VERSION ""

NS_ :

BS_:

BU_: FUSION CCU EOP_R BMS MCU_F Shifter EOP_F MCU_R

BO_ 278 FD_VCU1: 8 FUSION
 SG_ PwrSta : 63|3@0+ (1,0) [0|5] "" CCU,EOP_R,BMS,MCU_F,Shifter,EOP_F,MCU_R
 SG_ DCDCVoltSetpoint : 55|8@0+ (0.0235,12) [12|17.9925] "V" CCU
 SG_ DCDCEnaReq : 40|1@0+ (1,0) [0|1] "" CCU
 SG_ Fr_MCUEnaReq : 41|1@0+ (1,0) [0|1] "" MCU_F
 SG_ Rr_MCUEnaReq : 42|1@0+ (1,0) [0|1] "" MCU_R
 SG_ HVBatCnctReq : 43|1@0+ (1,0) [0|1] "" BMS
 SG_ ActiveDischReq : 44|1@0+ (1,0) [0|1] "" MCU_F,MCU_R
 SG_ PrkReq : 45|1@0+ (1,0) [0|1] "" Vector__XXX
 SG_ Fr_ActvDmpDisabReq : 46|1@0+ (1,0) [0|1] "" MCU_F
 SG_ Rr_ActvDmpDisabReq : 47|1@0+ (1,0) [0|1] "" MCU_R
 SG_ HVSysReadyToCharge : 33|2@0+ (1,0) [0|3] "" CCU
 SG_ ShiftGearPosn : 38|3@0+ (1,0) [0|7] "" MCU_F,Shifter,MCU_R
 SG_ LVChrgFuncStaChk : 25|2@0+ (1,0) [0|2] "" Vector__XXX
 SG_ MSA_Crl_Sta : 31|3@0+ (1,0) [0|7] "" Vector__XXX
 SG_ DemoModeStaChk : 17|2@0+ (1,0) [0|2] "" Vector__XXX
 SG_ CoastDwModeStaChk : 19|2@0+ (1,0) [0|2] "" Vector__XXX
 SG_ DynoModeStaChk : 21|2@0+ (1,0) [0|2] "" Vector__XXX
 SG_ Dr_SeatSta : 23|2@0+ (1,0) [0|2] "" Vector__XXX
 SG_ RC_VCU1 : 15|4@0+ (1,0) [0|14] "" CCU,BMS,MCU_F,MCU_R
 SG_ CS_VCU1 : 7|8@0+ (1,0) [0|255] "" CCU,BMS,MCU_F,MCU_R

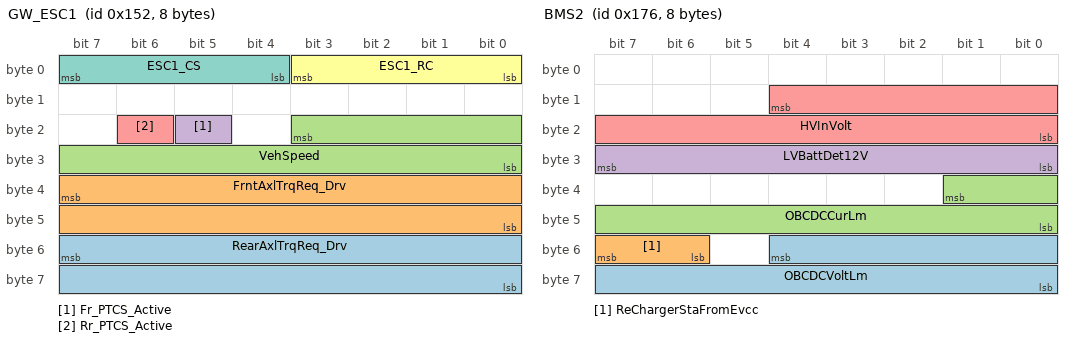
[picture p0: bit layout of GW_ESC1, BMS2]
BO_ 338 GW_ESC1: 8 FUSION
 SG_ RearAxlTrqReq_Drv : 55|16@0+ (0.5,-5300) [0|5300] "Nm" Vector__XXX
 SG_ FrntAxlTrqReq_Drv : 39|16@0+ (0.5,-5300) [0|5300] "Nm" Vector__XXX
 SG_ VehSpeed : 19|12@0+ (0.125,0) [0|255.875] "km/h" CCU,EOP_R,BMS,MCU_F,Shifter,EOP_F,MCU_R
 SG_ Fr_PTCS_Active : 21|1@0+ (1,0) [0|1] "" Vector__XXX
 SG_ Rr_PTCS_Active : 22|1@0+ (1,0) [0|1] "" Vector__XXX
 SG_ ESC1_RC : 3|4@0+ (1,0) [0|15] "" Vector__XXX
 SG_ ESC1_CS : 7|4@0+ (1,0) [0|15] "" Vector__XXX

BO_ 340 FD_VCU2: 24 FUSION
 SG_ Fr_TorqMin : 179|12@0+ (1,-1022) [-1022|0] "Nm" MCU_F
 SG_ Fr_TorqMax : 175|12@0+ (1,0) [0|1022] "Nm" MCU_F
 SG_ Fr_IdcMin : 155|12@0+ (1,-1022) [-1022|0] "A" MCU_F
 SG_ Fr_IdcMax : 151|12@0+ (1,0) [0|1022] "A" MCU_F
 SG_ Fr_TMTqReq : 135|16@0+ (1,-530) [-530|530] "Nm" MCU_F
 SG_ Rr_TMTqReq : 119|16@0+ (1,-530) [-530|530] "Nm" MCU_R
 SG_ Fr_UdcMin : 99|12@0+ (1,0) [0|1022] "V" MCU_F
 SG_ Fr_UdcMax : 95|12@0+ (1,0) [0|1022] "V" MCU_F
 SG_ Rr_UdcMin : 75|12@0+ (1,0) [0|1022] "V" MCU_R
 SG_ Rr_UdcMax : 71|12@0+ (1,0) [0|1022] "V" MCU_R
 SG_ Rr_TorqMin : 51|12@0+ (1,-1022) [-1022|0] "Nm" MCU_R
 SG_ Rr_TorqMax : 47|12@0+ (1,0) [0|1022] "Nm" MCU_R
 SG_ Rr_IdcMin : 27|12@0+ (1,-1022) [-1022|0] "A" MCU_R
 SG_ Rr_IdcMax : 23|12@0+ (1,0) [0|1022] "A" MCU_R
 SG_ RC_VCU2_CAN1 : 15|4@0+ (1,0) [0|15] "" MCU_F,MCU_R
 SG_ CS_VCU2_CAN1 : 7|8@0+ (1,0) [0|255] "" MCU_F,MCU_R

BO_ 369 BMS1: 16 BMS
 SG_ HVBPwrAvailChrg30 : 115|12@0+ (0.2,0) [0|819] "KW" FUSION
 SG_ HVBPwrAvailDchrg30 : 111|12@0+ (0.2,0) [0|819] "KW" FUSION
 SG_ HVBPwrAvailChrg : 91|12@0+ (0.2,0) [0|819] "KW" FUSION
 SG_ HVBPwrAvailDchrg : 87|12@0+ (0.2,0) [0|819] "KW" FUSION
 SG_ HVBPwrAvailChrg60 : 67|12@0+ (0.2,0) [0|819] "KW" FUSION
 SG_ HVBPwrAvailDchrg60 : 63|12@0+ (0.2,0) [0|819] "KW" FUSION
 SG_ HVBattCurr : 46|15@0+ (0.1,-1000) [-1000|2276.5] "A" FUSION
 SG_ HVBattVolt : 28|13@0+ (0.1,0) [0|819] "V" FUSION
 SG_ BMSRolCnct_1 : 15|4@0+ (1,0) [0|15] "" FUSION
 SG_ BMSChckSum_1 : 7|8@0+ (1,0) [0|255] "" FUSION

BO_ 374 BMS2: 8 BMS
 SG_ OBCDCVoltLm : 52|13@0+ (0.1,0) [0|819] "V" FUSION
 SG_ ReChargerStaFromEvcc : 55|2@0+ (1,0) [0|3] "" FUSION
 SG_ OBCDCCurLm : 33|10@0+ (0.1,-25.5) [-25.5|76.7] "A" FUSION
 SG_ LVBattDet12V : 31|8@0+ (0.1,0) [0|25.4] "V" FUSION
 SG_ HVInVolt : 12|13@0+ (0.1,0) [0|819] "V" FUSION

BO_ 378 BMS6: 12 BMS
 SG_ BMS_Warn_1 : 88|1@0+ (1,0) [0|1] "" FUSION
 SG_ BMS_Warn_2 : 89|1@0+ (1,0) [0|1] "" FUSION
 SG_ BMS_Warn_3 : 90|1@0+ (1,0) [0|1] "" FUSION
 SG_ BMS_Warn_4 : 91|1@0+ (1,0) [0|1] "" FUSION
 SG_ BMS_Warn_5 : 92|1@0+ (1,0) [0|1] "" FUSION
 SG_ BMS_Warn_6 : 93|1@0+ (1,0) [0|1] "" FUSION
 SG_ BMS_Warn_7 : 94|1@0+ (1,0) [0|1] "" FUSION
 SG_ BMS_Warn_8 : 95|1@0+ (1,0) [0|1] "" FUSION
 SG_ HVBOvrTempWarn : 81|2@0+ (1,0) [0|2] "" FUSION
 SG_ HVBUndrTempWarn : 83|2@0+ (1,0) [0|2] "" FUSION
 SG_ HVBOvrVoltErr : 84|1@0+ (1,0) [0|1] "" FUSION
 SG_ HVBUndrVoltErr : 85|1@0+ (1,0) [0|1] "" FUSION
 SG_ HVBShrtChrgCurrErr : 86|1@0+ (1,0) [0|1] "" FUSION
 SG_ HVBShrtDischrgCurrErr : 87|1@0+ (1,0) [0|1] "" FUSION
 SG_ HVBOvrChrgCurrErr : 72|1@0+ (1,0) [0|1] "" FUSION
 SG_ HVBOvrDchrgCurErr : 73|1@0+ (1,0) [0|1] "" FUSION
 SG_ HVBOvrTempErr : 74|1@0+ (1,0) [0|1] "" FUSION
 SG_ HVBUndrTempErr : 75|1@0+ (1,0) [0|1] "" FUSION
 SG_ HVBOvrSOCErr : 76|1@0+ (1,0) [0|1] "" FUSION
 SG_ HVBUndrSOCErr : 77|1@0+ (1,0) [0|1] "" FUSION
 SG_ HVBSOCJumpError : 78|1@0+ (1,0) [0|1] "" FUSION
 SG_ HVBHVILErr : 79|1@0+ (1,0) [0|1] "" FUSION
 SG_ DCChrgSysShockErr : 64|1@0+ (1,0) [0|1] "" FUSION
 SG_ BMS_READY : 65|1@0+ (1,0) [0|1] "" FUSION
 SG_ HVBContactorSta : 66|1@0+ (1,0) [0|1] "" FUSION
 SG_ HVBPrechrgSta : 69|2@0+ (1,0) [0|3] "" FUSION
 SG_ HVBTempDiffErr : 70|1@0+ (1,0) [0|1] "" FUSION
 SG_ HVILSta : 71|1@0+ (1,0) [0|1] "" FUSION
 SG_ HVBattReady4Pre : 57|2@0+ (1,0) [0|2] "" FUSION
 SG_ ChrgPlugSta : 59|2@0+ (1,0) [0|3] "" FUSION
 SG_ ExtChrgSta : 61|2@0+ (1,0) [0|3] "" FUSION
 SG_ HVBPreheatPrecoolSta : 63|2@0+ (1,0) [0|2] "" FUSION
 SG_ IsoDetSta : 48|1@0+ (1,0) [0|1] "" FUSION
 SG_ SystemUncomErr : 49|1@0+ (1,0) [0|1] "" FUSION
 SG_ CellUnconsistErr : 50|1@0+ (1,0) [0|1] "" FUSION
 SG_ HVBCellOvrVoltWarn : 53|2@0+ (1,0) [0|2] "" FUSION
 SG_ HVBCellUdrVoltWarn : 55|2@0+ (1,0) [0|2] "" FUSION
 SG_ HVBCellOvrVoltErr : 40|1@0+ (1,0) [0|1] "" FUSION
 SG_ HVBCellUndrVoltErr : 41|1@0+ (1,0) [0|1] "" FUSION
 SG_ HVBCellUnbalanErr : 42|1@0+ (1,0) [0|1] "" FUSION
 SG_ ChrgInLockReq : 45|2@0+ (1,0) [0|2] "" FUSION
 SG_ DisChrgPlugErr : 47|2@0+ (1,0) [0|3] "" FUSION
 SG_ HVBChrgErr : 39|8@0+ (1,0) [0|255] "" FUSION
 SG_ V2LSta : 25|2@0+ (1,0) [0|3] "" FUSION
 SG_ BMSRolCnct : 15|4@0+ (1,0) [0|15] "" FUSION
 SG_ BMSChckSum : 7|8@0+ (1,0) [0|255] "" FUSION

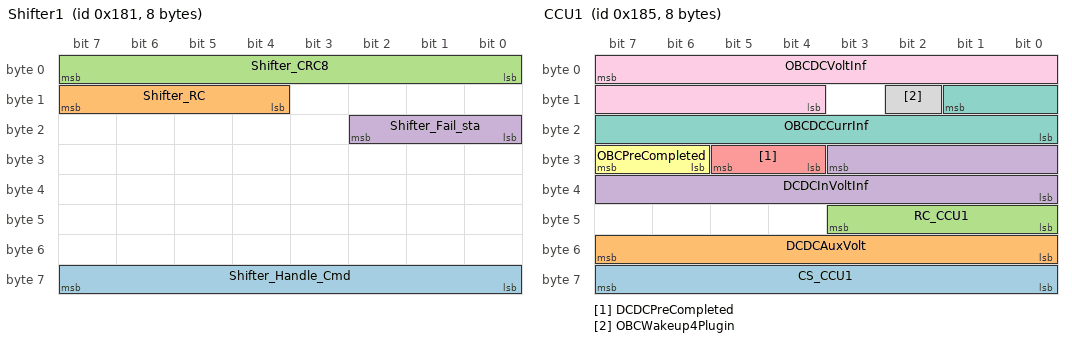
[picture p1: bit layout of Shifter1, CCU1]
BO_ 385 Shifter1: 8 Shifter
 SG_ Shifter_Handle_Cmd : 63|8@0+ (1,0) [0|255] "" FUSION
 SG_ Shifter_RC : 15|4@0+ (1,0) [0|15] "" FUSION
 SG_ Shifter_CRC8 : 7|8@0+ (1,0) [0|255] "" FUSION
 SG_ Shifter_Fail_sta : 18|3@0+ (1,0) [0|7] "" FUSION

BO_ 386 FD_THCM1: 20 FUSION
 SG_ Rr_Coolanttemp : 144|9@0+ (1,-40) [-40|214] "Deg^C" MCU_R
 SG_ Rr_Coolantflow : 150|6@0+ (0.25,0) [0|15.75] "L/min" MCU_R
 SG_ FD_AGS_Cmd : 143|8@0+ (1,0) [0|255] "" Vector__XXX
 SG_ sigClntTHvBattOut : 135|8@0+ (0.5,-40) [-40|85] "Deg^C" Vector__XXX
 SG_ sigCbnSolarLeft : 127|8@0+ (5,0) [0|1265] "W" Vector__XXX
 SG_ CabinMode : 115|4@0+ (1,0) [0|9] "" Vector__XXX
 SG_ BatteryMode : 118|3@0+ (1,0) [0|5] "" Vector__XXX
 SG_ FD_RecyAuto_Cmd : 111|3@0+ (1,0) [0|6] "" Vector__XXX
 SG_ sigCbnSolarRight : 103|8@0+ (5,0) [0|1265] "W" Vector__XXX
 SG_ sigAmbAirT : 95|8@0+ (0.5,-40) [-40|85] "Deg^C" Vector__XXX
 SG_ sigCbnAirT : 87|8@0+ (0.5,-40) [-40|85] "Deg^C" Vector__XXX
 SG_ sigCbnPTCPwrAct : 79|8@0+ (50,0) [0|12650] "W" Vector__XXX
 SG_ sigClmtCmprPwrAct : 71|8@0+ (50,0) [0|12650] "W" Vector__XXX
 SG_ Fr_Coolantflow : 61|6@0+ (0.25,0) [0|15.75] "L/min" MCU_F
 SG_ EDriveMode : 63|2@0+ (1,0) [0|2] "" Vector__XXX
 SG_ sigSetTempZon1St : 53|6@0+ (0.5,17) [17|32] "Deg^C" Vector__XXX
 SG_ HPThermalRecoveryReq : 55|2@0+ (1,0) [0|1] "" Vector__XXX
 SG_ sigSetTempZon2St : 45|6@0+ (0.5,17) [17|32] "Deg^C" Vector__XXX
 SG_ sigHvacSt : 46|1@0+ (1,0) [0|1] "" Vector__XXX
 SG_ sigRecircSt : 47|1@0+ (1,0) [0|1] "" Vector__XXX
 SG_ sigSetTempZon3St : 37|6@0+ (0.5,17) [17|32] "Deg^C" Vector__XXX
 SG_ sigDfrstSt : 38|1@0+ (1,0) [0|1] "" Vector__XXX
 SG_ CCU_SyncLampSts : 39|1@0+ (1,0) [0|1] "" Vector__XXX
 SG_ sigAirIntenZon3St : 27|4@0+ (1,0) [0|15] "" Vector__XXX
 SG_ sigAirIntenZon1St : 31|4@0+ (1,0) [0|15] "" Vector__XXX
 SG_ sigWindDirZon3St : 18|3@0+ (1,0) [0|7] "" Vector__XXX
 SG_ CCU_FrtOnOffLampSts : 19|1@0+ (1,0) [0|1] "" Vector__XXX
 SG_ sigWindDirZon1St : 22|3@0+ (1,0) [0|7] "" Vector__XXX
 SG_ CCU_RrOnOffLampSts : 23|1@0+ (1,0) [0|1] "" Vector__XXX
 SG_ Fr_Coolanttemp : 0|9@0+ (1,-40) [-40|214] "Deg^C" MCU_F
 SG_ CCU_ACMaxLampSts : 1|1@0+ (1,0) [0|1] "" Vector__XXX
 SG_ CCU_AutoLampSts : 2|1@0+ (1,0) [0|1] "" Vector__XXX
 SG_ CCU_AutoMidLampSts : 3|1@0+ (1,0) [0|1] "" Vector__XXX
 SG_ CCU_EcoSts : 4|1@0+ (1,0) [0|1] "" Vector__XXX
 SG_ CCU_Dispaly_Request : 5|1@0+ (1,0) [0|1] "" Vector__XXX
 SG_ CCU_ACLampSts : 6|1@0+ (1,0) [0|1] "" Vector__XXX
 SG_ CCU_HEATMaxLampSts : 7|1@0+ (1,0) [0|1] "" Vector__XXX

BO_ 389 CCU1: 8 CCU
 SG_ CS_CCU1 : 63|8@0+ (1,0) [0|255] "" FUSION
 SG_ DCDCAuxVolt : 55|8@0+ (0.047,8) [8|19.938] "V" FUSION
 SG_ RC_CCU1 : 43|4@0+ (1,0) [0|15] "" FUSION
 SG_ DCDCInVoltInf : 27|12@0+ (0.25,0) [0|1023.5] "V" FUSION
 SG_ DCDCPreCompleted : 29|2@0+ (1,0) [0|2] "" FUSION
 SG_ OBCPreCompleted : 31|2@0+ (1,0) [0|2] "" FUSION
 SG_ OBCDCCurrInf : 9|10@0+ (0.1,-25.5) [-25.5|76.7] "A" FUSION
 SG_ OBCWakeup4Plugin : 10|1@0+ (1,0) [0|1] "" FUSION
 SG_ OBCDCVoltInf : 7|12@0+ (0.3,0) [0|1228.2] "V" FUSION

BO_ 390 FD_THCM2: 20 FUSION
 SG_ CoolgFanActDuty : 159|8@0+ (0.5,0) [0|100] "%" Vector__XXX
 SG_ BatLoopActWtFlw : 151|8@0+ (0.1,-5) [-5|20] "L/min" Vector__XXX
 SG_ APTC_ActFrRiPwr : 143|8@0+ (25,0) [0|6375] "W" Vector__XXX
 SG_ FD_EWP1_Cmd : 135|8@0+ (1,0) [0|255] "" Vector__XXX
 SG_ FD_EWP2_Cmd : 127|8@0+ (1,0) [0|255] "" Vector__XXX
 SG_ FD_EWP3_Cmd : 119|8@0+ (1,0) [0|255] "" Vector__XXX
 SG_ FD_FrWPTCHeatPwr_Cmd : 103|16@0+ (1,0) [0|65535] "W" Vector__XXX
 SG_ FD_RrAPTCHeatPwr_Cmd : 95|8@0+ (25,0) [0|6375] "W" Vector__XXX
 SG_ FD_FrLeAPTCHeatPwr_Cmd : 87|8@0+ (25,0) [0|6375] "W" Vector__XXX
 SG_ FD_FrRiAPTCHeatPwr_Cmd : 79|8@0+ (25,0) [0|6375] "W" Vector__XXX
 SG_ FD_TWV_Cmd : 71|8@0+ (0.392,0) [0|99.96] "%" Vector__XXX
 SG_ FD_EXV2_Cmd : 49|10@0+ (1,0) [0|576] "step" Vector__XXX
 SG_ CCU_CbnPreEstimdTi : 55|6@0+ (1,0) [0|63] "" Vector__XXX
 SG_ FD_EXV1_Cmd : 33|10@0+ (1,0) [0|576] "step" Vector__XXX
 SG_ CCU_CbnPreACWkSts : 35|2@0+ (1,0) [0|3] "" Vector__XXX
 SG_ DeiceModReq : 37|2@0+ (1,0) [0|3] "" Vector__XXX
 SG_ CCU_CbnPreSts : 39|2@0+ (1,0) [0|3] "" Vector__XXX
 SG_ FD_Comp_Cmd : 22|15@0+ (0.5,0) [0|8300] "RPM" Vector__XXX
 SG_ CCU_HiVoltageReq : 23|1@0+ (1,0) [0|1] "" Vector__XXX
 SG_ FD_FWV_Cmd : 8|1@0+ (1,0) [0|1] "" Vector__XXX
 SG_ ACSubMode : 11|3@0+ (1,0) [0|7] "" Vector__XXX
 SG_ FD_SOTXV_Cmd : 12|1@0+ (1,0) [0|1] "" Vector__XXX
 SG_ FD_SOV1_Cmd : 13|1@0+ (1,0) [0|1] "" Vector__XXX
 SG_ FD_SOV2_Cmd : 14|1@0+ (1,0) [0|1] "" Vector__XXX
 SG_ FD_SOV3_Cmd : 15|1@0+ (1,0) [0|1] "" Vector__XXX
 SG_ FD_Blower_Cmd : 7|8@0+ (0.8,0) [0|200] "%" Vector__XXX

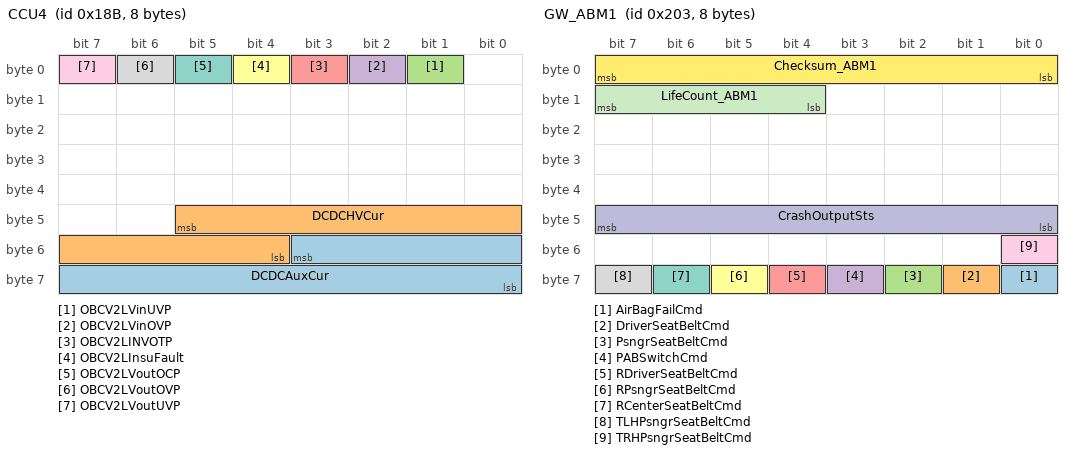
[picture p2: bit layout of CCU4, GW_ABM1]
BO_ 395 CCU4: 8 CCU
 SG_ DCDCAuxCur : 51|12@0+ (0.1,0) [0|409.5] "A" FUSION
 SG_ DCDCHVCur : 45|10@0+ (0.02,0) [0|20.46] "A" FUSION
 SG_ OBCV2LVinUVP : 1|1@0+ (1,0) [0|1] "" FUSION
 SG_ OBCV2LVinOVP : 2|1@0+ (1,0) [0|1] "" FUSION
 SG_ OBCV2LINVOTP : 3|1@0+ (1,0) [0|1] "" FUSION
 SG_ OBCV2LInsuFault : 4|1@0+ (1,0) [0|1] "" FUSION
 SG_ OBCV2LVoutOCP : 5|1@0+ (1,0) [0|1] "" FUSION
 SG_ OBCV2LVoutOVP : 6|1@0+ (1,0) [0|1] "" FUSION
 SG_ OBCV2LVoutUVP : 7|1@0+ (1,0) [0|1] "" FUSION

BO_ 402 MCU_R1: 32 MCU_R
 SG_ Rr_EDUTqReqFbk : 243|12@0+ (1,-1022) [-1022|1022] "Nm" FUSION
 SG_ Rr_MCUEnaSta : 244|1@0+ (1,0) [0|1] "" FUSION
 SG_ Rr_EDUOpratingSta : 245|1@0+ (1,0) [0|1] "" FUSION
 SG_ Rr_EDURotateDirction : 247|2@0+ (1,0) [0|2] "" FUSION
 SG_ Rr_EDURealTMTq : 227|12@0+ (1,-1022) [-1022|1022] "Nm" FUSION
 SG_ Rr_TMSpd : 215|16@0+ (1,-17000) [-17000|17000] "RPM" FUSION
 SG_ Rr_MCUReady4Pre : 200|1@0+ (1,0) [0|1] "" FUSION
 SG_ Rr_ActvDmpDisabSta : 201|1@0+ (1,0) [0|1] "" FUSION
 SG_ Rr_EDUDrtSta : 202|1@0+ (1,0) [0|1] "" FUSION
 SG_ Rr_MCUDischrgSta : 203|1@0+ (1,0) [0|1] "" FUSION
 SG_ Rr_MCUReady : 207|1@0+ (1,0) [0|1] "" FUSION
 SG_ Rr_MCUDCBusVolt : 191|16@0+ (0.1,0) [0|4000] "V" FUSION
 SG_ Rr_MCUDCBusCurr : 174|15@0+ (0.1,-1500) [-1500|1500] "A" FUSION
 SG_ Rr_MCUTemp : 167|9@0+ (1,-40) [-40|254] "Deg^C" FUSION
 SG_ Rr_TMTemp : 144|9@0+ (1,-40) [-40|254] "Deg^C" FUSION
 SG_ Rr_MCUErr : 143|8@0+ (1,0) [0|255] "" FUSION
 SG_ Rr_TMid : 126|15@0+ (0.1,-1500) [-1500|1500] "A" FUSION
 SG_ Rr_TMiq : 110|15@0+ (0.1,-1500) [-1500|1500] "A" FUSION
 SG_ Rr_MotorAvailTq : 91|12@0+ (1,0) [0|1022] "Nm" FUSION
 SG_ Rr_RegenAvailTq : 87|12@0+ (1,-1022) [-1022|0] "Nm" FUSION
 SG_ Rr_MCUIGN_sta : 72|1@0+ (1,0) [0|1] "" FUSION
 SG_ Rr_Reserved_bits : 79|7@0+ (1,0) [0|127] "" FUSION
 SG_ Rr_MCUBAT : 71|8@0+ (0.1,0) [0|25.4] "V" FUSION
 SG_ Rr_MCUSysSta : 59|4@0+ (1,0) [0|15] "" FUSION
 SG_ MCUWarn_R : 10|3@0+ (1,0) [0|7] "" FUSION
 SG_ Rr_MCU1RolCnt : 15|4@0+ (1,0) [0|15] "" FUSION
 SG_ Rr_MCU1Chksum : 7|8@0+ (1,0) [0|255] "" FUSION

BO_ 406 MCU_F1: 32 MCU_F
 SG_ Fr_EDUTqReqFbk : 243|12@0+ (1,-1022) [-1022|1022] "Nm" FUSION
 SG_ Fr_MCUEnaSta : 244|1@0+ (1,0) [0|1] "" FUSION
 SG_ Fr_EDUOpratingSta : 245|1@0+ (1,0) [0|1] "" FUSION
 SG_ Fr_EDURotateDirction : 247|2@0+ (1,0) [0|2] "" FUSION
 SG_ Fr_EDURealTMTq : 227|12@0+ (1,-1022) [-1022|1022] "Nm" FUSION
 SG_ Fr_TMSpd : 215|16@0+ (1,-17000) [-17000|17000] "RPM" FUSION
 SG_ Fr_MCUReady4Pre : 200|1@0+ (1,0) [0|1] "" FUSION
 SG_ Fr_ActvDmpDisabSta : 201|1@0+ (1,0) [0|1] "" FUSION
 SG_ Fr_EDUDrtSta : 202|1@0+ (1,0) [0|1] "" FUSION
 SG_ Fr_MCUDischrgSta : 203|1@0+ (1,0) [0|1] "" FUSION
 SG_ Fr_MCUDCBusVolt : 191|16@0+ (0.1,0) [0|4000] "V" FUSION
 SG_ Fr_MCUDCBusCurr : 174|15@0+ (0.1,-1500) [-1500|1500] "A" FUSION
 SG_ Fr_MCUTemp : 167|9@0+ (1,-40) [-40|254] "Deg^C" FUSION
 SG_ Fr_TMTemp : 144|9@0+ (1,-40) [-40|254] "Deg^C" FUSION
 SG_ Fr_MCUErr : 143|8@0+ (1,0) [0|255] "" FUSION
 SG_ Fr_TMid : 126|15@0+ (0.1,-1500) [-1500|1500] "A" FUSION
 SG_ Fr_TMiq : 110|15@0+ (0.1,-1500) [-1500|1500] "A" FUSION
 SG_ Fr_MotorAvailTq : 91|12@0+ (1,0) [0|1022] "Nm" FUSION
 SG_ Fr_RegenAvailTq : 87|12@0+ (1,-1022) [-1022|0] "Nm" FUSION
 SG_ Fr_MCUIGN_sta : 72|1@0+ (1,0) [0|1] "" FUSION
 SG_ Fr_Reserved_bits : 79|7@0+ (1,0) [0|127] "" FUSION
 SG_ Fr_MCUBAT : 71|8@0+ (0.1,0) [0|25.4] "V" FUSION
 SG_ Fr_MCUSysSta : 59|4@0+ (1,0) [0|15] "" FUSION
 SG_ MCUWarn_F : 10|3@0+ (1,0) [0|7] "" FUSION
 SG_ Fr_MCUReady : 11|1@0+ (1,0) [0|1] "" FUSION
 SG_ Fr_MCU1RolCnt : 15|4@0+ (1,0) [0|15] "" FUSION
 SG_ Fr_MCU1Chksum : 7|8@0+ (1,0) [0|255] "" FUSION

BO_ 408 MCU_F2: 12 MCU_F
 SG_ Fr_LLCTemp : 80|9@0+ (1,-40) [-40|214] "Deg^C" FUSION
 SG_ Fr_LLCflowReq : 87|6@0+ (0.25,0) [0|15.5] "L/min" FUSION
 SG_ Fr_EOP_SpdSet : 67|12@0+ (1,0) [0|4000] "RPM" FUSION
 SG_ Fr_Failcode1 : 63|8@0+ (1,0) [0|255] "" FUSION
 SG_ Fr_Failcode2 : 55|8@0+ (1,0) [0|255] "" FUSION
 SG_ Fr_Failcodehistory1 : 41|2@0+ (1,0) [0|2] "" FUSION
 SG_ Fr_Failcodehistory2 : 43|2@0+ (1,0) [0|2] "" FUSION
 SG_ Fr_TMTempWarn : 45|2@0+ (1,0) [0|3] "" FUSION
 SG_ Fr_MCUTempWarn : 47|2@0+ (1,0) [0|3] "" FUSION
 SG_ Fr_CoolanttempReq : 24|9@0+ (1,-40) [-40|214] "Deg^C" FUSION
 SG_ Fr_MCU2RolCnt : 15|4@0+ (1,0) [0|15] "" FUSION
 SG_ Fr_MCU2Chksum : 7|8@0+ (1,0) [0|255] "" FUSION
 SG_ MCU_F_ResetCnt_Sta : 23|8@0+ (1,0) [0|255] "" FUSION

BO_ 412 MCU_R2: 12 MCU_R
 SG_ Rr_LLCTemp : 80|9@0+ (1,-40) [-40|214] "Deg^C" FUSION
 SG_ Rr_LLCflowReq : 87|6@0+ (0.25,0) [0|15.5] "L/min" FUSION
 SG_ Rr_EOP_SpdSet : 67|12@0+ (1,0) [0|4000] "RPM" FUSION
 SG_ Rr_Failcode1 : 63|8@0+ (1,0) [0|255] "" FUSION
 SG_ Rr_Failcode2 : 55|8@0+ (1,0) [0|255] "" FUSION
 SG_ Rr_Failcodehistory1 : 41|2@0+ (1,0) [0|2] "" FUSION
 SG_ Rr_Failcodehistory2 : 43|2@0+ (1,0) [0|2] "" FUSION
 SG_ Rr_TMTempWarn : 45|2@0+ (1,0) [0|3] "" FUSION
 SG_ Rr_MCUTempWarn : 47|2@0+ (1,0) [0|3] "" FUSION
 SG_ Rr_CoolanttempReq : 24|9@0+ (1,-40) [-40|214] "" FUSION
 SG_ Rr_MCU2RolCnt : 15|4@0+ (1,0) [0|15] "" FUSION
 SG_ Rr_MCU2Chksum : 7|8@0+ (1,0) [0|255] "" FUSION
 SG_ MCU_R_ResetCnt_Sta : 23|8@0+ (1,0) [0|255] "" FUSION

BO_ 470 CCU2: 12 CCU
 SG_ OBCFaultSta : 89|2@0+ (1,0) [0|3] "" FUSION
 SG_ DCDCFaultSta : 91|2@0+ (1,0) [0|3] "" FUSION
 SG_ OBCReady4Pre : 92|1@0+ (1,0) [0|1] "" FUSION
 SG_ DCDCReady4Pre : 93|1@0+ (1,0) [0|1] "" FUSION
 SG_ OBCTemp : 87|9@0+ (0.3,-48) [-48|105.3] "Deg^C" FUSION
 SG_ DCDCTemp : 79|8@0+ (0.75,-48) [-48|142.5] "Deg^C" FUSION
 SG_ OBCDCP : 57|10@0+ (20,-7000) [-7000|13440] "W" FUSION
 SG_ DCDCEnaSta : 58|1@0+ (1,0) [0|1] "" FUSION
 SG_ OBCPluginSta : 59|1@0+ (1,0) [0|1] "" FUSION
 SG_ OBCEnaSta : 60|1@0+ (1,0) [0|1] "" FUSION
 SG_ OBCACCurrInf : 55|10@0+ (0.125,-40) [-40|87.75] "A" FUSION
 SG_ OBCACVoltInf : 35|12@0+ (0.1,0) [0|409.4] "V" FUSION
 SG_ OBC_AC_Cur_Lim : 37|2@0+ (1,0) [0|3] "" FUSION
 SG_ OBCV2LSta : 9|2@0+ (1,0) [0|2] "" FUSION
 SG_ ReqOBCV2LEna : 11|2@0+ (1,0) [0|2] "" FUSION
 SG_ RC_CCU2 : 15|4@0+ (1,0) [0|15] "" FUSION
 SG_ CS_CCU2 : 7|8@0+ (1,0) [0|255] "" FUSION

BO_ 515 GW_ABM1: 8 FUSION
 SG_ AirBagFailCmd : 56|1@0+ (1,0) [0|1] "" Vector__XXX
 SG_ DriverSeatBeltCmd : 57|1@0+ (1,0) [0|1] "" Vector__XXX
 SG_ PsngrSeatBeltCmd : 58|1@0+ (1,0) [0|1] "" Vector__XXX
 SG_ PABSwitchCmd : 59|1@0+ (1,0) [0|1] "" Vector__XXX
 SG_ RDriverSeatBeltCmd : 60|1@0+ (1,0) [0|1] "" Vector__XXX
 SG_ RPsngrSeatBeltCmd : 61|1@0+ (1,0) [0|1] "" Vector__XXX
 SG_ RCenterSeatBeltCmd : 62|1@0+ (1,0) [0|1] "" Vector__XXX
 SG_ TLHPsngrSeatBeltCmd : 63|1@0+ (1,0) [0|1] "" Vector__XXX
 SG_ TRHPsngrSeatBeltCmd : 48|1@0+ (1,0) [0|1] "" Vector__XXX
 SG_ CrashOutputSts : 47|8@0+ (1,0) [0|16] "" BMS
 SG_ LifeCount_ABM1 : 15|4@0+ (1,0) [0|15] "" Vector__XXX
 SG_ Checksum_ABM1 : 7|8@0+ (1,0) [0|255] "" Vector__XXX

BO_ 534 FD_BCM1: 16 FUSION
 SG_ DrDoorSW : 120|1@0+ (1,0) [0|1] "" Vector__XXX
 SG_ PsDoorSW : 121|1@0+ (1,0) [0|1] "" Vector__XXX
 SG_ RLDoorSW : 122|1@0+ (1,0) [0|1] "" Vector__XXX
 SG_ RRDoorSW : 123|1@0+ (1,0) [0|1] "" Vector__XXX
 SG_ AllDoorSW : 124|1@0+ (1,0) [0|1] "" Vector__XXX
 SG_ DoorLockIND : 125|1@0+ (1,0) [0|1] "" Vector__XXX
 SG_ HoodSW : 126|1@0+ (1,0) [0|1] "" Vector__XXX
 SG_ Tailgate_SW : 127|1@0+ (1,0) [0|1] "" Vector__XXX
 SG_ CTDCtrl : 113|2@0+ (1,0) [0|3] "" BMS
 SG_ Fr_ChargingDoorCtrl : 115|2@0+ (1,0) [0|3] "" Vector__XXX
 SG_ Rr_ChargingDoorCtrl : 117|2@0+ (1,0) [0|3] "" Vector__XXX
 SG_ CTDLockSW : 118|1@0+ (1,0) [0|1] "" Vector__XXX
 SG_ CTDUnlockSW : 119|1@0+ (1,0) [0|1] "" Vector__XXX
 SG_ MirrorDefog : 104|1@0+ (1,0) [0|1] "" Vector__XXX
 SG_ Rr_Defog : 105|1@0+ (1,0) [0|1] "" Vector__XXX
 SG_ TrunkRel : 106|1@0+ (1,0) [0|1] "" Vector__XXX
 SG_ TailgateHDSW : 107|1@0+ (1,0) [0|1] "" Vector__XXX
 SG_ MirrorCtrl : 109|2@0+ (1,0) [0|3] "" Vector__XXX
 SG_ Fr_Wiper_H : 110|1@0+ (1,0) [0|1] "" Vector__XXX
 SG_ Fr_Wiper_L : 111|1@0+ (1,0) [0|1] "" Vector__XXX
 SG_ Rr_Wiper : 96|1@0+ (1,0) [0|1] "" Vector__XXX
 SG_ WiperFixMode : 97|1@0+ (1,0) [0|1] "" Vector__XXX
 SG_ WasherCtrl : 99|2@0+ (1,0) [0|3] "" Vector__XXX
 SG_ L_Beam : 100|1@0+ (1,0) [0|1] "" Vector__XXX
 SG_ H_Beam : 101|1@0+ (1,0) [0|1] "" Vector__XXX
 SG_ PosLamp : 102|1@0+ (1,0) [0|1] "" Vector__XXX
 SG_ LDRL : 103|1@0+ (1,0) [0|1] "" Vector__XXX
 SG_ RDRL : 88|1@0+ (1,0) [0|1] "" Vector__XXX
 SG_ ReverseLamp : 89|1@0+ (1,0) [0|1] "" Vector__XXX
 SG_ BrakeLamp : 90|1@0+ (1,0) [0|1] "" Vector__XXX
 SG_ LBSD : 91|1@0+ (1,0) [0|1] "" Vector__XXX
 SG_ RBSD : 92|1@0+ (1,0) [0|1] "" Vector__XXX
 SG_ Fr_FogLamp : 93|1@0+ (1,0) [0|1] "" Vector__XXX
 SG_ Rr_FogLamp : 94|1@0+ (1,0) [0|1] "" Vector__XXX
 SG_ HazardSW : 95|1@0+ (1,0) [0|1] "" Vector__XXX
 SG_ LTurnLP : 80|1@0+ (1,0) [0|1] "" Vector__XXX
 SG_ RTurnLP : 81|1@0+ (1,0) [0|1] "" Vector__XXX
 SG_ AntitheftSta : 83|2@0+ (1,0) [0|3] "" Vector__XXX
 SG_ AntiTheftSeatFold : 84|1@0+ (1,0) [0|1] "" Vector__XXX
 SG_ CrashDetd : 85|1@0+ (1,0) [0|1] "" Vector__XXX
 SG_ L_APM_WdwEnable : 87|1@0+ (1,0) [0|1] "" Vector__XXX
 SG_ Dimmer : 78|7@0+ (1,0) [0|100] "%" Shifter
 SG_ LockSetting : 79|1@0+ (1,0) [0|1] "" Vector__XXX
 SG_ BCM_Buzzer_Req : 64|1@0+ (1,0) [0|1] "" Vector__XXX
 SG_ TailgateRemote : 66|2@0+ (1,0) [0|3] "" Vector__XXX
 SG_ RoomLampL : 67|1@0+ (1,0) [0|1] "" Vector__XXX
 SG_ RoomLampH : 68|1@0+ (1,0) [0|1] "" Vector__XXX
 SG_ DimmerEN : 69|1@0+ (1,0) [0|1] "" Shifter
 SG_ BCM_DoorLock_Sta : 70|1@0+ (1,0) [0|1] "" Vector__XXX
 SG_ HornCtrl : 71|1@0+ (1,0) [0|1] "" Vector__XXX
 SG_ WisrBootReason : 7|32@0+ (1,0) [0|4.294967295E9] "" Vector__XXX
 SG_ PmicBootReason : 39|8@0+ (1,0) [0|255] "" Vector__XXX

BO_ 560 BMS9: 64 BMS
 SG_ CellVoltage01 : 503|16@0+ (1,0) [0|65534] "mV" FUSION
 SG_ CellVoltage02 : 487|16@0+ (1,0) [0|65534] "mV" FUSION
 SG_ CellVoltage03 : 471|16@0+ (1,0) [0|65534] "mV" FUSION
 SG_ CellVoltage04 : 455|16@0+ (1,0) [0|65534] "mV" FUSION
 SG_ CellVoltage05 : 439|16@0+ (1,0) [0|65534] "mV" FUSION
 SG_ CellVoltage06 : 423|16@0+ (1,0) [0|65534] "mV" FUSION
 SG_ CellVoltage07 : 407|16@0+ (1,0) [0|65534] "mV" FUSION
 SG_ CellVoltage08 : 391|16@0+ (1,0) [0|65534] "mV" FUSION
 SG_ CellVoltage09 : 375|16@0+ (1,0) [0|65534] "mV" FUSION
 SG_ CellVoltage10 : 359|16@0+ (1,0) [0|65534] "mV" FUSION
 SG_ CellVoltage11 : 343|16@0+ (1,0) [0|65534] "mV" FUSION
 SG_ CellVoltage12 : 327|16@0+ (1,0) [0|65534] "mV" FUSION
 SG_ CellVoltage13 : 311|16@0+ (1,0) [0|65534] "mV" FUSION
 SG_ CellVoltage14 : 295|16@0+ (1,0) [0|65534] "mV" FUSION
 SG_ CellVoltage15 : 279|16@0+ (1,0) [0|65534] "mV" FUSION
 SG_ CellVoltage16 : 263|16@0+ (1,0) [0|65534] "mV" FUSION
 SG_ CellVoltage17 : 247|16@0+ (1,0) [0|65534] "mV" FUSION
 SG_ CellVoltage18 : 231|16@0+ (1,0) [0|65534] "mV" FUSION
 SG_ CellVoltage19 : 215|16@0+ (1,0) [0|65534] "mV" FUSION
 SG_ CellVoltage20 : 199|16@0+ (1,0) [0|65534] "mV" FUSION
 SG_ CellVoltage21 : 183|16@0+ (1,0) [0|65534] "mV" FUSION
 SG_ CellVoltage22 : 167|16@0+ (1,0) [0|65534] "mV" FUSION
 SG_ CellVoltage23 : 151|16@0+ (1,0) [0|65534] "mV" FUSION
 SG_ CellVoltage24 : 135|16@0+ (1,0) [0|65534] "mV" FUSION
 SG_ CellVoltage25 : 119|16@0+ (1,0) [0|65534] "mV" FUSION
 SG_ CellVoltage26 : 103|16@0+ (1,0) [0|65534] "mV" FUSION
 SG_ CellVoltage27 : 87|16@0+ (1,0) [0|65534] "mV" FUSION
 SG_ CellVoltage28 : 71|16@0+ (1,0) [0|65534] "mV" FUSION
 SG_ CellVoltage29 : 55|16@0+ (1,0) [0|65534] "mV" FUSION
 SG_ CellVoltage30 : 39|16@0+ (1,0) [0|65534] "mV" FUSION
 SG_ CellVoltage31 : 23|16@0+ (1,0) [0|65534] "mV" FUSION
 SG_ CellVoltage32 : 7|16@0+ (1,0) [0|65534] "mV" FUSION

BO_ 561 BMS10: 64 BMS
 SG_ CellVoltage33 : 503|16@0+ (1,0) [0|65534] "mV" FUSION
 SG_ CellVoltage34 : 487|16@0+ (1,0) [0|65534] "mV" FUSION
 SG_ CellVoltage35 : 471|16@0+ (1,0) [0|65534] "mV" FUSION
 SG_ CellVoltage36 : 455|16@0+ (1,0) [0|65534] "mV" FUSION
 SG_ CellVoltage37 : 439|16@0+ (1,0) [0|65534] "mV" FUSION
 SG_ CellVoltage38 : 423|16@0+ (1,0) [0|65534] "mV" FUSION
 SG_ CellVoltage39 : 407|16@0+ (1,0) [0|65534] "mV" FUSION
 SG_ CellVoltage40 : 391|16@0+ (1,0) [0|65534] "mV" FUSION
 SG_ CellVoltage41 : 375|16@0+ (1,0) [0|65534] "mV" FUSION
 SG_ CellVoltage42 : 359|16@0+ (1,0) [0|65534] "mV" FUSION
 SG_ CellVoltage43 : 343|16@0+ (1,0) [0|65534] "mV" FUSION
 SG_ CellVoltage44 : 327|16@0+ (1,0) [0|65534] "mV" FUSION
 SG_ CellVoltage45 : 311|16@0+ (1,0) [0|65534] "mV" FUSION
 SG_ CellVoltage46 : 295|16@0+ (1,0) [0|65534] "mV" FUSION
 SG_ CellVoltage47 : 279|16@0+ (1,0) [0|65534] "mV" FUSION
 SG_ CellVoltage48 : 263|16@0+ (1,0) [0|65534] "mV" FUSION
 SG_ CellVoltage49 : 247|16@0+ (1,0) [0|65534] "mV" FUSION
 SG_ CellVoltage50 : 231|16@0+ (1,0) [0|65534] "mV" FUSION
 SG_ CellVoltage51 : 215|16@0+ (1,0) [0|65534] "mV" FUSION
 SG_ CellVoltage52 : 199|16@0+ (1,0) [0|65534] "mV" FUSION
 SG_ CellVoltage53 : 183|16@0+ (1,0) [0|65534] "mV" FUSION
 SG_ CellVoltage54 : 167|16@0+ (1,0) [0|65534] "mV" FUSION
 SG_ CellVoltage55 : 151|16@0+ (1,0) [0|65534] "mV" FUSION
 SG_ CellVoltage56 : 135|16@0+ (1,0) [0|65534] "mV" FUSION
 SG_ CellVoltage57 : 119|16@0+ (1,0) [0|65534] "mV" FUSION
 SG_ CellVoltage58 : 103|16@0+ (1,0) [0|65534] "mV" FUSION
 SG_ CellVoltage59 : 87|16@0+ (1,0) [0|65534] "mV" FUSION
 SG_ CellVoltage60 : 71|16@0+ (1,0) [0|65534] "mV" FUSION
 SG_ CellVoltage61 : 55|16@0+ (1,0) [0|65534] "mV" FUSION
 SG_ CellVoltage62 : 39|16@0+ (1,0) [0|65534] "mV" FUSION
 SG_ CellVoltage63 : 23|16@0+ (1,0) [0|65534] "mV" FUSION
 SG_ CellVoltage64 : 7|16@0+ (1,0) [0|65534] "mV" FUSION

BO_ 562 BMS11: 64 BMS
 SG_ CellVoltage65 : 503|16@0+ (1,0) [0|65534] "mV" FUSION
 SG_ CellVoltage66 : 487|16@0+ (1,0) [0|65534] "mV" FUSION
 SG_ CellVoltage67 : 471|16@0+ (1,0) [0|65534] "mV" FUSION
 SG_ CellVoltage68 : 455|16@0+ (1,0) [0|65534] "mV" FUSION
 SG_ CellVoltage69 : 439|16@0+ (1,0) [0|65534] "mV" FUSION
 SG_ CellVoltage70 : 423|16@0+ (1,0) [0|65534] "mV" FUSION
 SG_ CellVoltage71 : 407|16@0+ (1,0) [0|65534] "mV" FUSION
 SG_ CellVoltage72 : 391|16@0+ (1,0) [0|65534] "mV" FUSION
 SG_ CellVoltage73 : 375|16@0+ (1,0) [0|65534] "mV" FUSION
 SG_ CellVoltage74 : 359|16@0+ (1,0) [0|65534] "mV" FUSION
 SG_ CellVoltage75 : 343|16@0+ (1,0) [0|65534] "mV" FUSION
 SG_ CellVoltage76 : 327|16@0+ (1,0) [0|65534] "mV" FUSION
 SG_ CellVoltage77 : 311|16@0+ (1,0) [0|65534] "mV" FUSION
 SG_ CellVoltage78 : 295|16@0+ (1,0) [0|65534] "mV" FUSION
 SG_ CellVoltage79 : 279|16@0+ (1,0) [0|65534] "mV" FUSION
 SG_ CellVoltage80 : 263|16@0+ (1,0) [0|65534] "mV" FUSION
 SG_ CellVoltage81 : 247|16@0+ (1,0) [0|65534] "mV" FUSION
 SG_ CellVoltage82 : 231|16@0+ (1,0) [0|65534] "mV" FUSION
 SG_ CellVoltage83 : 215|16@0+ (1,0) [0|65534] "mV" FUSION
 SG_ CellVoltage84 : 199|16@0+ (1,0) [0|65534] "mV" FUSION
 SG_ CellVoltage85 : 183|16@0+ (1,0) [0|65534] "mV" FUSION
 SG_ CellVoltage86 : 167|16@0+ (1,0) [0|65534] "mV" FUSION
 SG_ CellVoltage87 : 151|16@0+ (1,0) [0|65534] "mV" FUSION
 SG_ CellVoltage88 : 135|16@0+ (1,0) [0|65534] "mV" FUSION
 SG_ CellVoltage89 : 119|16@0+ (1,0) [0|65534] "mV" FUSION
 SG_ CellVoltage90 : 103|16@0+ (1,0) [0|65534] "mV" FUSION
 SG_ CellVoltage91 : 87|16@0+ (1,0) [0|65534] "mV" FUSION
 SG_ CellVoltage92 : 71|16@0+ (1,0) [0|65534] "mV" FUSION
 SG_ CellVoltage93 : 55|16@0+ (1,0) [0|65534] "mV" FUSION
 SG_ CellVoltage94 : 39|16@0+ (1,0) [0|65534] "mV" FUSION
 SG_ CellVoltage95 : 23|16@0+ (1,0) [0|65534] "mV" FUSION
 SG_ CellVoltage96 : 7|16@0+ (1,0) [0|65534] "mV" FUSION

BO_ 563 BMS12: 64 BMS
 SG_ CellVoltage97 : 503|16@0+ (1,0) [0|65534] "mV" FUSION
 SG_ CellVoltage98 : 487|16@0+ (1,0) [0|65534] "mV" FUSION
 SG_ CellVoltage99 : 471|16@0+ (1,0) [0|65534] "mV" FUSION
 SG_ CellVoltage100 : 455|16@0+ (1,0) [0|65534] "mV" FUSION
 SG_ CellVoltage101 : 439|16@0+ (1,0) [0|65534] "mV" FUSION
 SG_ CellVoltage102 : 423|16@0+ (1,0) [0|65534] "mV" FUSION
 SG_ CellVoltage103 : 407|16@0+ (1,0) [0|65534] "mV" FUSION
 SG_ CellVoltage104 : 391|16@0+ (1,0) [0|65534] "mV" FUSION
 SG_ CellVoltage105 : 375|16@0+ (1,0) [0|65534] "mV" FUSION
 SG_ CellVoltage106 : 359|16@0+ (1,0) [0|65534] "mV" FUSION
 SG_ CellVoltage107 : 343|16@0+ (1,0) [0|65534] "mV" FUSION
 SG_ CellVoltage108 : 327|16@0+ (1,0) [0|65534] "mV" FUSION
 SG_ CellVoltage109 : 311|16@0+ (1,0) [0|65534] "mV" FUSION
 SG_ CellVoltage110 : 295|16@0+ (1,0) [0|65534] "mV" FUSION
 SG_ CellVoltage111 : 279|16@0+ (1,0) [0|65534] "mV" FUSION
 SG_ CellVoltage112 : 263|16@0+ (1,0) [0|65534] "mV" FUSION
 SG_ CellVoltage113 : 247|16@0+ (1,0) [0|65534] "mV" FUSION
 SG_ CellVoltage114 : 231|16@0+ (1,0) [0|65534] "mV" FUSION
 SG_ CellVoltage115 : 215|16@0+ (1,0) [0|65534] "mV" FUSION
 SG_ CellVoltage116 : 199|16@0+ (1,0) [0|65534] "mV" FUSION
 SG_ CellVoltage117 : 183|16@0+ (1,0) [0|65534] "mV" FUSION
 SG_ CellVoltage118 : 167|16@0+ (1,0) [0|65534] "mV" FUSION
 SG_ CellVoltage119 : 151|16@0+ (1,0) [0|65534] "mV" FUSION
 SG_ CellVoltage120 : 135|16@0+ (1,0) [0|65534] "mV" FUSION
 SG_ CellVoltage121 : 119|16@0+ (1,0) [0|65534] "mV" FUSION
 SG_ CellVoltage122 : 103|16@0+ (1,0) [0|65534] "mV" FUSION
 SG_ CellVoltage123 : 87|16@0+ (1,0) [0|65534] "mV" FUSION
 SG_ CellVoltage124 : 71|16@0+ (1,0) [0|65534] "mV" FUSION
 SG_ CellVoltage125 : 55|16@0+ (1,0) [0|65534] "mV" FUSION
 SG_ CellVoltage126 : 39|16@0+ (1,0) [0|65534] "mV" FUSION
 SG_ CellVoltage127 : 23|16@0+ (1,0) [0|65534] "mV" FUSION
 SG_ CellVoltage128 : 7|16@0+ (1,0) [0|65534] "mV" FUSION

BO_ 809 BMS3: 32 BMS
 SG_ HVBattSOCDis : 255|8@0+ (0.4,0) [0|100] "%" FUSION
 SG_ HVBattSOC : 247|8@0+ (0.4,0) [0|100] "%" FUSION
 SG_ HVBattPackVolt : 228|13@0+ (0.1,0) [0|819] "V" FUSION
 SG_ HVBChrgPwr : 223|10@0+ (0.1,0) [0|102.2] "KWh" FUSION
 SG_ HVBDrvPwr : 199|10@0+ (0.1,0) [0|102.2] "KWh" FUSION
 SG_ HVBFullChrgPwr : 177|10@0+ (0.1,0) [0|102.2] "KWh" FUSION
 SG_ RemainChrgTime : 175|12@0+ (1,0) [0|4094] "MINUTE" FUSION
 SG_ HVBSOH : 167|8@0+ (0.4,0) [0|100] "%" FUSION
 SG_ HVBIsoImpedenceP : 150|15@0+ (0.01,0) [0|327.66] "Megaohm" FUSION
 SG_ HVBIsoImpedenceN : 134|15@0+ (0.01,0) [0|327.66] "Megaohm" FUSION
 SG_ Battsystfail_Num : 127|8@0+ (1,0) [0|253] "" FUSION
 SG_ RechrgCyc : 97|18@0+ (1,0) [0|262142] "CYCLE" FUSION
 SG_ CellType : 101|4@0+ (1,0) [0|7] "" FUSION
 SG_ ACChrgCurrDis : 86|15@0+ (0.1,-1000) [-1000|2276.5] "A" FUSION
 SG_ HVBChrgPwrTotal : 57|18@0+ (1,0) [0|262143] "KWh" FUSION
 SG_ HVBDrvPwrTotal : 33|18@0+ (1,0) [0|262143] "KWh" FUSION
 SG_ HVBattSOCDiff : 213|6@0+ (1,0) [0|63] "%" FUSION
 SG_ SOC_UseLimit : 215|2@0+ (1,0) [0|3] "" FUSION
 SG_ BMS_HVBattCellBalance_Sta : 200|1@0+ (1,0) [0|1] "" FUSION

BO_ 820 BMS8: 48 BMS
 SG_ MainPosstandard : 279|16@0+ (1,0) [0|65535] "" FUSION
 SG_ MainChrgRlyNegOutterVoltage : 263|16@0+ (1,0) [0|65535] "" FUSION
 SG_ MainChrgRlyPosOutterVoltage : 247|16@0+ (1,0) [0|65535] "" FUSION
 SG_ MainRlyNegOutterVoltage : 231|16@0+ (1,0) [0|65535] "" FUSION
 SG_ G0standard : 215|16@0+ (1,0) [0|65535] "" FUSION
 SG_ MainRlyPosOutterVoltage : 199|16@0+ (1,0) [0|65535] "" FUSION
 SG_ MainRlyPosInnerVoltage : 183|16@0+ (1,0) [0|65535] "" FUSION
 SG_ MainChrgRlyPosSta : 175|8@0+ (1,0) [0|255] "" FUSION
 SG_ MainChrgRlyNegSta : 167|8@0+ (1,0) [0|255] "" FUSION
 SG_ MainRlyNegSta : 159|8@0+ (1,0) [0|255] "" FUSION
 SG_ MainRlyPosSta : 151|8@0+ (1,0) [0|255] "" FUSION
 SG_ MainChrgRlyNegDriReq : 143|8@0+ (1,0) [0|255] "" FUSION
 SG_ MainChrgRlyPosDriReq : 135|8@0+ (1,0) [0|255] "" FUSION
 SG_ MainRlyNegDriReq : 127|8@0+ (1,0) [0|255] "" FUSION
 SG_ MainRlyPosDriReq : 119|8@0+ (1,0) [0|255] "" FUSION
 SG_ TherRunawayErrMask : 87|32@0+ (1,0) [0|4.294967295E9] "" FUSION
 SG_ DCChrgCurrent : 55|32@0+ (0.01,-2000) [-2000|6000] "A" FUSION
 SG_ DCChrgVoltage : 39|16@0+ (0.1,0) [0|6553.5] "V" FUSION
 SG_ ACChrgStop : 31|8@0+ (1,0) [0|255] "" FUSION
 SG_ DCChrgStop : 23|8@0+ (1,0) [0|255] "" FUSION
 SG_ CurrentErrorID : 7|16@0+ (1,0) [0|65535] "" FUSION

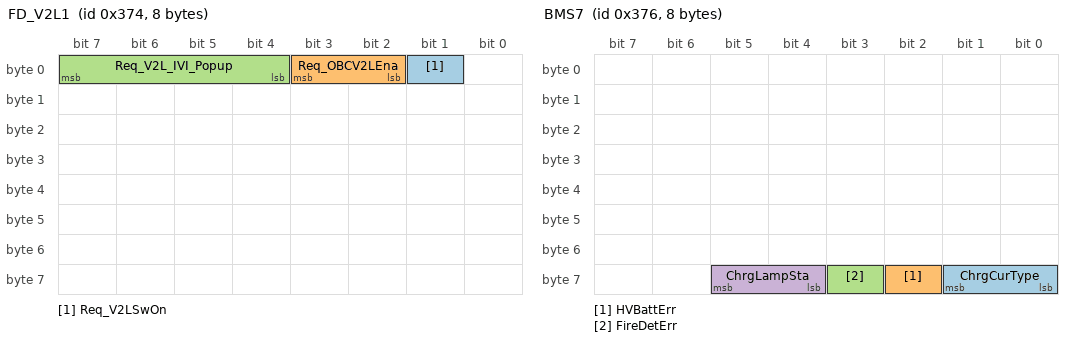
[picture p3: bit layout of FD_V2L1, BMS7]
BO_ 884 FD_V2L1: 8 FUSION
 SG_ Req_V2LSwOn : 1|1@0+ (1,0) [0|1] "" Vector__XXX
 SG_ Req_OBCV2LEna : 3|2@0+ (1,0) [0|2] "" CCU
 SG_ Req_V2L_IVI_Popup : 7|4@0+ (1,0) [0|6] "" Vector__XXX

BO_ 886 BMS7: 8 BMS
 SG_ ChrgCurType : 57|2@0+ (1,0) [0|3] "" FUSION
 SG_ HVBattErr : 58|1@0+ (1,0) [0|1] "" FUSION
 SG_ FireDetErr : 59|1@0+ (1,0) [0|1] "" FUSION
 SG_ ChrgLampSta : 61|2@0+ (1,0) [0|3] "" FUSION

BO_ 898 CCU3: 8 CCU
 SG_ CCU_ACportNTC1 : 63|8@0+ (1,-48) [-48|206] "Deg^C" FUSION
 SG_ CCU_ACportNTC2 : 55|8@0+ (1,-48) [-48|206] "Deg^C" FUSION

BO_ 921 MCU_F3: 8 MCU_F
 SG_ Fr_MCU_SW_Ver : 55|16@0+ (1,0) [0|65535] "" FUSION
 SG_ Fr_MCU_HW_Ver : 39|16@0+ (1,0) [0|65535] "" FUSION

BO_ 925 MCU_R3: 8 MCU_R
 SG_ Rr_MCU3_SW_Ver : 55|16@0+ (1,0) [0|65535] "" FUSION
 SG_ Rr_MCU3_HW_Ver : 39|16@0+ (1,0) [0|65535] "" FUSION

BO_ 992 BMS4: 48 BMS
 SG_ HVBCellVoltMax : 375|16@0+ (1,0) [0|65533] "mV" FUSION
 SG_ HVBCellVoltMin : 359|16@0+ (1,0) [0|65533] "mV" FUSION
 SG_ CellTempAvg : 351|8@0+ (1,-40) [-40|213] "Deg^C" FUSION
 SG_ MaxCellVolt_Num : 343|8@0+ (1,0) [0|253] "" FUSION
 SG_ MinCellVolt_Num : 335|8@0+ (1,0) [0|253] "" FUSION
 SG_ MaxCellTemp_Num : 327|8@0+ (1,0) [0|253] "" FUSION
 SG_ MinCellTemp_Num : 319|8@0+ (1,0) [0|253] "" FUSION
 SG_ HVBMTempMax : 311|8@0+ (1,-40) [-40|213] "Deg^C" FUSION
 SG_ HVBMTempMin : 303|8@0+ (1,-40) [-40|213] "Deg^C" FUSION
 SG_ Mtemp16 : 159|8@0+ (1,-40) [-40|213] "Deg^C" FUSION
 SG_ Mtemp17 : 151|8@0+ (1,-40) [-40|213] "Deg^C" FUSION
 SG_ Mtemp18 : 143|8@0+ (1,-40) [-40|213] "Deg^C" FUSION
 SG_ Mtemp19 : 135|8@0+ (1,-40) [-40|213] "Deg^C" FUSION
 SG_ Mtemp20 : 127|8@0+ (1,-40) [-40|213] "Deg^C" FUSION
 SG_ Mtemp01 : 119|8@0+ (1,-40) [-40|213] "Deg^C" FUSION
 SG_ Mtemp02 : 111|8@0+ (1,-40) [-40|213] "Deg^C" FUSION
 SG_ Mtemp03 : 103|8@0+ (1,-40) [-40|213] "Deg^C" FUSION
 SG_ Mtemp04 : 95|8@0+ (1,-40) [-40|213] "Deg^C" FUSION
 SG_ Mtemp05 : 87|8@0+ (1,-40) [-40|213] "Deg^C" FUSION
 SG_ Mtemp06 : 79|8@0+ (1,-40) [-40|213] "Deg^C" FUSION
 SG_ Mtemp07 : 71|8@0+ (1,-40) [-40|213] "Deg^C" FUSION
 SG_ Mtemp08 : 63|8@0+ (1,-40) [-40|213] "Deg^C" FUSION
 SG_ Mtemp09 : 55|8@0+ (1,-40) [-40|213] "Deg^C" FUSION
 SG_ Mtemp10 : 47|8@0+ (1,-40) [-40|213] "Deg^C" FUSION
 SG_ Mtemp11 : 39|8@0+ (1,-40) [-40|213] "Deg^C" FUSION
 SG_ Mtemp12 : 31|8@0+ (1,-40) [-40|213] "Deg^C" FUSION
 SG_ Mtemp13 : 23|8@0+ (1,-40) [-40|213] "Deg^C" FUSION
 SG_ Mtemp14 : 15|8@0+ (1,-40) [-40|213] "Deg^C" FUSION
 SG_ Mtemp15 : 7|8@0+ (1,-40) [-40|213] "Deg^C" FUSION

CM_ SG_ 278 PwrSta "Vehicle Power Status";
CM_ SG_ 278 DCDCVoltSetpoint "DCDC voltage setpoint  request";
CM_ SG_ 278 DCDCEnaReq "DCDC Enable Request";
CM_ SG_ 278 Fr_MCUEnaReq "Front MCU Enable Request";
CM_ SG_ 278 Rr_MCUEnaReq "Rear MCU Enable Request";
CM_ SG_ 278 HVBatCnctReq "HV Battery Pack Connect Request";
CM_ SG_ 278 ActiveDischReq "System Active Discharge Request";
CM_ SG_ 278 PrkReq "Parking Request";
CM_ SG_ 278 Fr_ActvDmpDisabReq "Front EDU Low Speed Active Damping Disable Request";
CM_ SG_ 278 Rr_ActvDmpDisabReq "Rear EDU Low Speed Active Damping Disable Request";
CM_ SG_ 278 HVSysReadyToCharge "To notify OBC if EV system is ready to be charged during plugin situation.";
CM_ SG_ 278 ShiftGearPosn "EV Selector Position Status/ Selector Position Status Signal Failure";
CM_ SG_ 278 LVChrgFuncStaChk "Silent charging function state check";
CM_ SG_ 278 MSA_Crl_Sta "MSA Status";
CM_ SG_ 278 DemoModeStaChk "Demo mode state check";
CM_ SG_ 278 CoastDwModeStaChk "Coastdown mode state check";
CM_ SG_ 278 DynoModeStaChk "Dyno mode state check";
CM_ SG_ 278 Dr_SeatSta "Driver seat switch state";
CM_ SG_ 278 RC_VCU1 "VCU1 4-bit rolling counter
It starts counting from 0, ends at 14 and returns to zero (0~14).";
CM_ SG_ 278 CS_VCU1 "VCU1 frame checksum 
x^8+x^4+x^3+x^2+1 
It shall use 0x00 as the start value and XOR value.";
CM_ SG_ 338 RearAxlTrqReq_Drv "Rear Axle DrivingTorque Limitation";
CM_ SG_ 338 FrntAxlTrqReq_Drv "Front Axle Driving Torque Limitation";
CM_ SG_ 338 VehSpeed "Vehicle Speed";
CM_ SG_ 338 Fr_PTCS_Active "Front Axle Torque Reduction Active";
CM_ SG_ 338 Rr_PTCS_Active "Rear Axle Torque Reduction Active";
CM_ SG_ 338 ESC1_RC "Rolling Counter of ESC1";
CM_ SG_ 338 ESC1_CS "Checksum of ESC1

complement = ((Sigma(first 15 halfbytes) + 2) XOR 0xFF)Checksum = complement MOD 0x10";
CM_ SG_ 340 Fr_TorqMin "min limit of negative torque";
CM_ SG_ 340 Fr_TorqMax "max limit of positive torque";
CM_ SG_ 340 Fr_IdcMin "E-Axle Idc limit min";
CM_ SG_ 340 Fr_IdcMax "E-Axle Idc limit max";
CM_ SG_ 340 Fr_TMTqReq "Front Traction Motor Torque Request";
CM_ SG_ 340 Rr_TMTqReq "Rear Traction Motor Torque Request";
CM_ SG_ 340 Fr_UdcMin "E-Axle Udc limit max";
CM_ SG_ 340 Fr_UdcMax "E-Axle Udc limit max";
CM_ SG_ 340 Rr_UdcMin "E-Axle Udc limit min";
CM_ SG_ 340 Rr_UdcMax "E-Axle Udc limit max";
CM_ SG_ 340 Rr_TorqMin "min limit of negative torque";
CM_ SG_ 340 Rr_TorqMax "max limit of positive torque";
CM_ SG_ 340 Rr_IdcMin "E-Axle Idc limit min";
CM_ SG_ 340 Rr_IdcMax "E-Axle Idc limit max";
CM_ SG_ 340 RC_VCU2_CAN1 "VCU2 4-bit rolling counter";
CM_ SG_ 340 CS_VCU2_CAN1 "VCU2 frame checksum(SAEJ1850)
x^8+x^4+x^3+x^2+1 
It shall use 0xFF as the start value and XOR value.";
CM_ SG_ 369 HVBPwrAvailChrg30 "HV battery available charging power 30 second";
CM_ SG_ 369 HVBPwrAvailDchrg30 "HV battery available discharge power 30 second";
CM_ SG_ 369 HVBPwrAvailChrg "HV battery available charging power";
CM_ SG_ 369 HVBPwrAvailDchrg "HV battery available discharge power";
CM_ SG_ 369 HVBPwrAvailChrg60 "HV battery available charging power 60 second";
CM_ SG_ 369 HVBPwrAvailDchrg60 "HV battery available discharge power 60 second";
CM_ SG_ 369 HVBattCurr "HV battery pack current";
CM_ SG_ 369 HVBattVolt "HV battery pack Volt";
CM_ SG_ 369 BMSRolCnct_1 "BMS RollingCount";
CM_ SG_ 369 BMSChckSum_1 "BMS CheckSum";
CM_ SG_ 374 OBCDCVoltLm "OBC DC Voltage Limit";
CM_ SG_ 374 ReChargerStaFromEvcc "ResarvationChargerStatusFromEVCC";
CM_ SG_ 374 OBCDCCurLm "OBC DC Current Limit";
CM_ SG_ 374 LVBattDet12V "12V Battery Detect";
CM_ SG_ 374 HVInVolt "HV Input voltage";
CM_ SG_ 378 BMS_Warn_1 "BMS Warning1";
CM_ SG_ 378 BMS_Warn_2 "BMS Warning2";
CM_ SG_ 378 BMS_Warn_3 "BMS Warning3";
CM_ SG_ 378 BMS_Warn_4 "BMS Warning4";
CM_ SG_ 378 BMS_Warn_5 "BMS Warning5";
CM_ SG_ 378 BMS_Warn_6 "BMS Warning6";
CM_ SG_ 378 BMS_Warn_7 "BMS Warning7";
CM_ SG_ 378 BMS_Warn_8 "BMS Warning8";
CM_ SG_ 378 HVBOvrTempWarn "Over temperature warn";
CM_ SG_ 378 HVBUndrTempWarn "Under temperature warn";
CM_ SG_ 378 HVBOvrVoltErr "Pack over Volt";
CM_ SG_ 378 HVBUndrVoltErr "Pack under Volt";
CM_ SG_ 378 HVBShrtChrgCurrErr "Short charge current";
CM_ SG_ 378 HVBShrtDischrgCurrErr "Short discharge current";
CM_ SG_ 378 HVBOvrChrgCurrErr "Over charge current";
CM_ SG_ 378 HVBOvrDchrgCurErr "Over discharge current";
CM_ SG_ 378 HVBOvrTempErr "Over temperature";
CM_ SG_ 378 HVBUndrTempErr "Under temperature";
CM_ SG_ 378 HVBOvrSOCErr "Over SOC";
CM_ SG_ 378 HVBUndrSOCErr "Under SOC";
CM_ SG_ 378 HVBSOCJumpError "SOC Jump Error";
CM_ SG_ 378 HVBHVILErr "HVIL hardware failed";
CM_ SG_ 378 DCChrgSysShockErr "DC Charge System Shock Error";
CM_ SG_ 378 BMS_READY "BMS ready";
CM_ SG_ 378 HVBContactorSta "HV battery contactor closed status";
CM_ SG_ 378 HVBPrechrgSta "BMS informs VCU HV battery precharge status";
CM_ SG_ 378 HVBTempDiffErr "Temperature Different Error";
CM_ SG_ 378 HVILSta "HVIL status";
CM_ SG_ 378 HVBattReady4Pre "BMS informs VCU HV battery is ready to be Precharged";
CM_ SG_ 378 ChrgPlugSta "Charger plug status";
CM_ SG_ 378 ExtChrgSta "External charging status";
CM_ SG_ 378 HVBPreheatPrecoolSta "BMS informs VCU HV battery is over heat or cold";
CM_ SG_ 378 IsoDetSta "Isolation Detection status. Send every 100ms and event trigger, especially power down";
CM_ SG_ 378 SystemUncomErr "System Uncompitable Error";
CM_ SG_ 378 CellUnconsistErr "Cell Unconsistency Error";
CM_ SG_ 378 HVBCellOvrVoltWarn "Cell over Volt warn";
CM_ SG_ 378 HVBCellUdrVoltWarn "Cell under Volt warn";
CM_ SG_ 378 HVBCellOvrVoltErr "Cell over Volt";
CM_ SG_ 378 HVBCellUndrVoltErr "Cell under Volt";
CM_ SG_ 378 HVBCellUnbalanErr "Cell unbalance";
CM_ SG_ 378 ChrgInLockReq "ChargeInlet Lock Request";
CM_ SG_ 378 DisChrgPlugErr "(Dis)Charger plug Error
0x0 : Normal
0x1 : plug-in incomplete
0x2 : (un)lock request invalid";
CM_ SG_ 378 HVBChrgErr "HVB Charge Error";
CM_ SG_ 378 V2LSta "V2L Adapter Status";
CM_ SG_ 378 BMSRolCnct "BMS RollingCount";
CM_ SG_ 378 BMSChckSum "BMS CheckSum";
CM_ SG_ 385 Shifter_Handle_Cmd "Shifter Control Unit handle Command(PRND)";
CM_ SG_ 385 Shifter_RC "shifter_rollingcounter";
CM_ SG_ 385 Shifter_CRC8 "shifter_checksum";
CM_ SG_ 385 Shifter_Fail_sta "Shifter fail status";
CM_ SG_ 386 Rr_Coolanttemp "LLC coolant temp";
CM_ SG_ 386 Rr_Coolantflow "LLC coolant flow rate";
CM_ SG_ 386 FD_AGS_Cmd "Fusion Domain AGS Position Request";
CM_ SG_ 386 sigClntTHvBattOut "battery coolant outlet temperature";
CM_ SG_ 386 sigCbnSolarLeft "Measured cabin sun exposure";
CM_ SG_ 386 CabinMode "Cabin Mode";
CM_ SG_ 386 BatteryMode "Battery Mode";
CM_ SG_ 386 FD_RecyAuto_Cmd "Auto recycle command";
CM_ SG_ 386 sigCbnSolarRight "Measured cabin sun exposure";
CM_ SG_ 386 sigAmbAirT "Environment temperature (outside ambient vehicle temperature)";
CM_ SG_ 386 sigCbnAirT "Cabin air temperature";
CM_ SG_ 386 sigCbnPTCPwrAct "Current power consumption FRONT AirPTC";
CM_ SG_ 386 sigClmtCmprPwrAct "Current power consumption AC compressor";
CM_ SG_ 386 Fr_Coolantflow "LLC coolant flow rate";
CM_ SG_ 386 EDriveMode "E-Drive Mode";
CM_ SG_ 386 sigSetTempZon1St "Feedback: Temperature set in the HVAC for Zone 1";
CM_ SG_ 386 HPThermalRecoveryReq "Heat Pump thermal reuse request";
CM_ SG_ 386 sigSetTempZon2St "Feedback: Temperature set in the HVAC for Zone 2";
CM_ SG_ 386 sigHvacSt "Status of the HVAC (ON / OFF)";
CM_ SG_ 386 sigRecircSt "Recirculation Status in the HVAC (Fre/Rec/Auto)";
CM_ SG_ 386 sigSetTempZon3St "Feedback: Temperature set in the HVAC for Zone 3";
CM_ SG_ 386 sigDfrstSt "Defrost Status in the HVAC (ON / AUTO)";
CM_ SG_ 386 CCU_SyncLampSts "Climate SYNC lamp state";
CM_ SG_ 386 sigAirIntenZon3St "Feedback FAN Level/Air Intensirty : 0-Max or Auto for zone 3";
CM_ SG_ 386 sigAirIntenZon1St "Feedback FAN Level/Air Intensirty : 0-Max or Auto for zone 1";
CM_ SG_ 386 sigWindDirZon3St "Feedback: WInd DirectionZone 3. 
Feed, Body and/or Auto";
CM_ SG_ 386 CCU_FrtOnOffLampSts "Front Climate On Off lamp state";
CM_ SG_ 386 sigWindDirZon1St "Feedback: WInd DirectionZone 1. 
Feed, Body, WIndscreen and/or Auto";
CM_ SG_ 386 CCU_RrOnOffLampSts "Rear Climate On Off lamp state";
CM_ SG_ 386 Fr_Coolanttemp "LLC coolant temp";
CM_ SG_ 386 CCU_ACMaxLampSts "Climate AC Max lamp state";
CM_ SG_ 386 CCU_AutoLampSts "Climate air conditionning Front  automatic mode lamp state";
CM_ SG_ 386 CCU_AutoMidLampSts "Climate air conditionning middle left automatic mode lamp state";
CM_ SG_ 386 CCU_EcoSts "Economic mode status";
CM_ SG_ 386 CCU_Dispaly_Request "Air Conditioner display reuqest trigger";
CM_ SG_ 386 CCU_ACLampSts "Climate AC lamp state";
CM_ SG_ 386 CCU_HEATMaxLampSts "Climate HEATING Max lamp state";
CM_ SG_ 389 CS_CCU1 "CCU1 frame checksum";
CM_ SG_ 389 DCDCAuxVolt "DC/DC Output Volt";
CM_ SG_ 389 RC_CCU1 "CCU1 4-bit rolling counter";
CM_ SG_ 389 DCDCInVoltInf "DC/DC Input Voltage Information";
CM_ SG_ 389 DCDCPreCompleted "DCDC Precharge Completed";
CM_ SG_ 389 OBCPreCompleted "OBC Precharge Completed";
CM_ SG_ 389 OBCDCCurrInf "OBC DC Current Information";
CM_ SG_ 389 OBCWakeup4Plugin "OBC Wake Up For Plugin";
CM_ SG_ 389 OBCDCVoltInf "OBC DC Voltage Information";
CM_ SG_ 390 CoolgFanActDuty "Cooling fan actual duty cycle (PWM)";
CM_ SG_ 390 BatLoopActWtFlw "Battery loop actual water flow";
CM_ SG_ 390 APTC_ActFrRiPwr "Air PTC actual power front right";
CM_ SG_ 390 FD_EWP1_Cmd "Fusion Domain RrTM Water Pump Command";
CM_ SG_ 390 FD_EWP2_Cmd "Fusion Domain FrTM Water Pump Command";
CM_ SG_ 390 FD_EWP3_Cmd "Fusion Domain Battery Water Pump Command";
CM_ SG_ 390 FD_FrWPTCHeatPwr_Cmd "Fusion Domain Front Water PTC Heat Power Request";
CM_ SG_ 390 FD_RrAPTCHeatPwr_Cmd "Fusion Domain Rear Air PTC Heat Power Request";
CM_ SG_ 390 FD_FrLeAPTCHeatPwr_Cmd "Fusion Domain Front Left Air PTC Heat Power Request";
CM_ SG_ 390 FD_FrRiAPTCHeatPwr_Cmd "Fusion Domain Front Right Air PTC Heat Power Request";
CM_ SG_ 390 FD_TWV_Cmd "Fusion Domain Three Way Valve Position Request";
CM_ SG_ 390 FD_EXV2_Cmd "Fusion Domain HPChiller EXV Command";
CM_ SG_ 390 CCU_CbnPreEstimdTi "Maximum Estimated Time to achieve the target temperature in minutes(Value 61,62 for reserved, value 63 for Invalid)
0x3d~0x3E:Reserved";
CM_ SG_ 390 FD_EXV1_Cmd "Fusion Domain Chiller EXV Command";
CM_ SG_ 390 CCU_CbnPreACWkSts "Cabin Preconditioning A/C work status";
CM_ SG_ 390 DeiceModReq "Deice mode request";
CM_ SG_ 390 CCU_CbnPreSts "Cabin Preconditioning Status
It shall stay as Off if A/C is turned on not by preconditioning request";
CM_ SG_ 390 FD_Comp_Cmd "Fusion Domain Compressor Request";
CM_ SG_ 390 CCU_HiVoltageReq "High voltage request";
CM_ SG_ 390 FD_FWV_Cmd "Fusion Domain Four Way Valve Position Request";
CM_ SG_ 390 ACSubMode "AC system sub mode";
CM_ SG_ 390 FD_SOTXV_Cmd "Fusion Domain SOTXV Command";
CM_ SG_ 390 FD_SOV1_Cmd "Fusion Domain SOV1 Command";
CM_ SG_ 390 FD_SOV2_Cmd "Fusion Domain SOV2 Command";
CM_ SG_ 390 FD_SOV3_Cmd "Fusion Domain SOV3 Command";
CM_ SG_ 390 FD_Blower_Cmd "Fusion Domain Blower Command";
CM_ SG_ 395 DCDCAuxCur "DC/DC Output Current";
CM_ SG_ 395 DCDCHVCur "DC/DC Input Current";
CM_ SG_ 395 OBCV2LVinUVP "OBC V2L INPUT UVP";
CM_ SG_ 395 OBCV2LVinOVP "OBC V2L INPUT OVP";
CM_ SG_ 395 OBCV2LINVOTP "OBC V2L INVERTER OTP";
CM_ SG_ 395 OBCV2LInsuFault "OBC V2L Insulation Fault";
CM_ SG_ 395 OBCV2LVoutOCP "OBC V2L OUTPUT OCP";
CM_ SG_ 395 OBCV2LVoutOVP "OBC V2L OUTPUT OVP";
CM_ SG_ 395 OBCV2LVoutUVP "OBC V2L OUTPUT UVP";
CM_ SG_ 402 Rr_EDUTqReqFbk "Rear EDU Torque Request Feedback";
CM_ SG_ 402 Rr_MCUEnaSta "Rear MCU Enable Status";
CM_ SG_ 402 Rr_EDUOpratingSta "Rear EDU Torque/Speed Status";
CM_ SG_ 402 Rr_EDURotateDirction "Rear EDU Direction Status";
CM_ SG_ 402 Rr_EDURealTMTq "Rear EDU Real Torque from TM";
CM_ SG_ 402 Rr_TMSpd "Rear TM speed";
CM_ SG_ 402 Rr_MCUReady4Pre "Rear MCU Ready for Precharge";
CM_ SG_ 402 Rr_ActvDmpDisabSta "Rear MCU Low speed active damping disable status";
CM_ SG_ 402 Rr_EDUDrtSta "Rear EDU Torque Derating Status";
CM_ SG_ 402 Rr_MCUDischrgSta "Rear MCU Discharge Status";
CM_ SG_ 402 Rr_MCUReady "Rear MCU Ready";
CM_ SG_ 402 Rr_MCUDCBusVolt "Rear MCU DC-Bus Voltage";
CM_ SG_ 402 Rr_MCUDCBusCurr "Rear  MCU DC Current";
CM_ SG_ 402 Rr_MCUTemp "Rear  MCU Temperature";
CM_ SG_ 402 Rr_TMTemp "Rear  TM Temperature";
CM_ SG_ 402 Rr_MCUErr "Rear  MCU Error Code";
CM_ SG_ 402 Rr_TMid "Rear  TM id Feedback";
CM_ SG_ 402 Rr_TMiq "Rear  TM iq Feedback";
CM_ SG_ 402 Rr_MotorAvailTq "Rear Motor Torque Available";
CM_ SG_ 402 Rr_RegenAvailTq "Rear RegenerationTorque Available";
CM_ SG_ 402 Rr_MCUIGN_sta "IGN ON/OFF Status";
CM_ SG_ 402 Rr_Reserved_bits "Rear  Reserved bits";
CM_ SG_ 402 Rr_MCUBAT "Rear  Bat Voltage";
CM_ SG_ 402 Rr_MCUSysSta "Rear MCU System Status";
CM_ SG_ 402 MCUWarn_R "MCU warning signal_Rear";
CM_ SG_ 402 Rr_MCU1RolCnt "Rear  MCU1 4 bits Process counter";
CM_ SG_ 402 Rr_MCU1Chksum "Rear  MCU1 Frame checksum(SAEJ1850) 
x^8+x^4+x^3+x^2+1
It shall use 0xFF as the start value and XOR value.";
CM_ SG_ 406 Fr_EDUTqReqFbk "Front EDU Torque Request Feedback";
CM_ SG_ 406 Fr_MCUEnaSta "Front MCU Enable Status";
CM_ SG_ 406 Fr_EDUOpratingSta "Front EDU Torque/Speed Status";
CM_ SG_ 406 Fr_EDURotateDirction "Front EDU Direction Status";
CM_ SG_ 406 Fr_EDURealTMTq "Front EDU Real Torque from TM";
CM_ SG_ 406 Fr_TMSpd "Front TM speed";
CM_ SG_ 406 Fr_MCUReady4Pre "Front MCU Ready for Precharge";
CM_ SG_ 406 Fr_ActvDmpDisabSta "Front MCU Low speed active damping disable status";
CM_ SG_ 406 Fr_EDUDrtSta "Front EDU Torque Derating Status";
CM_ SG_ 406 Fr_MCUDischrgSta "Front MCU Discharge Status";
CM_ SG_ 406 Fr_MCUDCBusVolt "Front MCU DC-Bus Voltage";
CM_ SG_ 406 Fr_MCUDCBusCurr "Front MCU DC Current";
CM_ SG_ 406 Fr_MCUTemp "Front MCU Temperature";
CM_ SG_ 406 Fr_TMTemp "Front TM Temperature";
CM_ SG_ 406 Fr_MCUErr "Front MCU Error Code";
CM_ SG_ 406 Fr_TMid "Front TM id Feedback";
CM_ SG_ 406 Fr_TMiq "Front TM iq Feedback";
CM_ SG_ 406 Fr_MotorAvailTq "Front Motor Torque Available";
CM_ SG_ 406 Fr_RegenAvailTq "Front RegenerationTorque Available";
CM_ SG_ 406 Fr_MCUIGN_sta "IGN ON/OFF Status";
CM_ SG_ 406 Fr_Reserved_bits "Front Reserved bits";
CM_ SG_ 406 Fr_MCUBAT "Front Bat Voltage";
CM_ SG_ 406 Fr_MCUSysSta "Front MCU System Status";
CM_ SG_ 406 MCUWarn_F "MCU warning signal_Front";
CM_ SG_ 406 Fr_MCUReady "Front MCU Ready";
CM_ SG_ 406 Fr_MCU1RolCnt "Front MCU1 4 bits Process counter";
CM_ SG_ 406 Fr_MCU1Chksum "Front MCU1 Frame checksum(SAEJ1850) 
x^8+x^4+x^3+x^2+1
It shall use 0xFF as the start value and XOR value.";
CM_ SG_ 408 Fr_LLCTemp "Front LLC temperature";
CM_ SG_ 408 Fr_LLCflowReq "Front request LLC flow rate";
CM_ SG_ 408 Fr_EOP_SpdSet "Front MCU request EOP Speed";
CM_ SG_ 408 Fr_Failcode1 "Front Detail fail code";
CM_ SG_ 408 Fr_Failcode2 "Front Detail fail code";
CM_ SG_ 408 Fr_Failcodehistory1 "Front Failcode history status";
CM_ SG_ 408 Fr_Failcodehistory2 "Front Failcode history status";
CM_ SG_ 408 Fr_TMTempWarn "FrontTM Temperature Warning";
CM_ SG_ 408 Fr_MCUTempWarn "Front MCU Temperature Warning";
CM_ SG_ 408 Fr_CoolanttempReq "LLC coolant temp Request";
CM_ SG_ 408 Fr_MCU2RolCnt "Front MCU2 4bits Process counter";
CM_ SG_ 408 Fr_MCU2Chksum "Front MCU2 Frame checksum(SAEJ1850) 
x^8+x^4+x^3+x^2+1
It shall use 0xFF as the start value and XOR value.";
CM_ SG_ 408 MCU_F_ResetCnt_Sta "Front  MCU Reset counter";
CM_ SG_ 412 Rr_LLCTemp "Rear  LLC temperature";
CM_ SG_ 412 Rr_LLCflowReq "Rear  request LLC flow rate";
CM_ SG_ 412 Rr_EOP_SpdSet "Rear  MCU request EOP Speed";
CM_ SG_ 412 Rr_Failcode1 "Rear  Detail fail code";
CM_ SG_ 412 Rr_Failcode2 "Rear  Detail fail code";
CM_ SG_ 412 Rr_Failcodehistory1 "Rear  Failcode history status";
CM_ SG_ 412 Rr_Failcodehistory2 "Rear Failcode history status";
CM_ SG_ 412 Rr_TMTempWarn "Rear TM Temperature Warning";
CM_ SG_ 412 Rr_MCUTempWarn "Rear MCU Temperature Warning";
CM_ SG_ 412 Rr_CoolanttempReq "LLC coolant temp Request";
CM_ SG_ 412 Rr_MCU2RolCnt "Rear MCU2 4bits Process counter";
CM_ SG_ 412 Rr_MCU2Chksum "Rear  MCU2 Frame checksum(SAEJ1850) 
x^8+x^4+x^3+x^2+1
It shall use 0xFF as the start value and XOR value.";
CM_ SG_ 412 MCU_R_ResetCnt_Sta "Rear MCU Reset counter";
CM_ SG_ 470 OBCFaultSta "OBC Fault Status";
CM_ SG_ 470 DCDCFaultSta "DCDC Fault Status";
CM_ SG_ 470 OBCReady4Pre "OBC Ready For Precharge";
CM_ SG_ 470 DCDCReady4Pre "DCDC Converter Ready For Precharge";
CM_ SG_ 470 OBCTemp "OBC Temperature";
CM_ SG_ 470 DCDCTemp "DC/DC Temperature";
CM_ SG_ 470 OBCDCP "OBC DC Power";
CM_ SG_ 470 DCDCEnaSta "DCDC status: HV operation enabled/disabled";
CM_ SG_ 470 OBCPluginSta "OBC Plugin Status";
CM_ SG_ 470 OBCEnaSta "Current Enable Status of OBC";
CM_ SG_ 470 OBCACCurrInf "OBC AC Current Information";
CM_ SG_ 470 OBCACVoltInf "OBC AC Voltage Information";
CM_ SG_ 470 OBC_AC_Cur_Lim "OBC AC Current Limit";
CM_ SG_ 470 OBCV2LSta "OBC V2L Status";
CM_ SG_ 470 ReqOBCV2LEna "Request OBC V2L Enable";
CM_ SG_ 470 RC_CCU2 "CCU2 4-bit rolling counter";
CM_ SG_ 470 CS_CCU2 "CCU2 frame checksum";
CM_ SG_ 515 AirBagFailCmd "Airbag system lamp status";
CM_ SG_ 515 DriverSeatBeltCmd "Driver Seat Belt lamp status";
CM_ SG_ 515 PsngrSeatBeltCmd "Passenger Seat Belt lamp status";
CM_ SG_ 515 PABSwitchCmd "PAB Switch lamp status";
CM_ SG_ 515 RDriverSeatBeltCmd "Rear driver seat belt lamp status";
CM_ SG_ 515 RPsngrSeatBeltCmd "Rear passenger seat belt lamp status";
CM_ SG_ 515 RCenterSeatBeltCmd "Rear center seat belt lamp status";
CM_ SG_ 515 TLHPsngrSeatBeltCmd "Third LH seatbelt lamp status";
CM_ SG_ 515 TRHPsngrSeatBeltCmd "Third RH seatbelt lamp status";
CM_ SG_ 515 CrashOutputSts "Crash Output Status";
CM_ SG_ 515 LifeCount_ABM1 "RollingCounter of ABM";
CM_ SG_ 515 Checksum_ABM1 "Check sum of ABM";
CM_ SG_ 534 DrDoorSW "Driver Side Door Switch";
CM_ SG_ 534 PsDoorSW "Passenger Side Door Switch";
CM_ SG_ 534 RLDoorSW "Rear Left Door Switch";
CM_ SG_ 534 RRDoorSW "Rear Right Door Switch";
CM_ SG_ 534 AllDoorSW "All Door Switch";
CM_ SG_ 534 DoorLockIND "Door Lock Indicator";
CM_ SG_ 534 HoodSW "Hood Switch";
CM_ SG_ 534 Tailgate_SW "Tailgate Switch";
CM_ SG_ 534 CTDCtrl "Door Lock Control";
CM_ SG_ 534 Fr_ChargingDoorCtrl "Front Charging Door Control";
CM_ SG_ 534 Rr_ChargingDoorCtrl "Rear Charging Door Control";
CM_ SG_ 534 CTDLockSW "Central Door Lock SW";
CM_ SG_ 534 CTDUnlockSW "Central Door Unlock SW";
CM_ SG_ 534 MirrorDefog "Mirror Defog";
CM_ SG_ 534 Rr_Defog "Rear Defog";
CM_ SG_ 534 TrunkRel "Trunk Release";
CM_ SG_ 534 TailgateHDSW "Tailgate Handle SW";
CM_ SG_ 534 MirrorCtrl "Mirror Control";
CM_ SG_ 534 Fr_Wiper_H "Front Wiper High";
CM_ SG_ 534 Fr_Wiper_L "Front Wiper LOW";
CM_ SG_ 534 Rr_Wiper "Rear Wiper";
CM_ SG_ 534 WiperFixMode "Wiper Fix Mode";
CM_ SG_ 534 WasherCtrl "WasherControl";
CM_ SG_ 534 L_Beam "Low Beam";
CM_ SG_ 534 H_Beam "High Beam";
CM_ SG_ 534 PosLamp "PositionLamp";
CM_ SG_ 534 LDRL "Left DRL";
CM_ SG_ 534 RDRL "Right DRL";
CM_ SG_ 534 ReverseLamp "ReverseLamp";
CM_ SG_ 534 BrakeLamp "BrakeLamp";
CM_ SG_ 534 LBSD "Left BSD";
CM_ SG_ 534 RBSD "Right BSD";
CM_ SG_ 534 Fr_FogLamp "Front Fog Lamp";
CM_ SG_ 534 Rr_FogLamp "Rear Fog Lamp";
CM_ SG_ 534 HazardSW "Hazard SW";
CM_ SG_ 534 LTurnLP "Left Turn Lamp";
CM_ SG_ 534 RTurnLP "Right Turn Lamp";
CM_ SG_ 534 AntitheftSta "Anti-theft Status";
CM_ SG_ 534 AntiTheftSeatFold "Anti-theft Seat Fold";
CM_ SG_ 534 CrashDetd "Crash Detected";
CM_ SG_ 534 L_APM_WdwEnable "Enable windows movement";
CM_ SG_ 534 Dimmer "Dimmer";
CM_ SG_ 534 LockSetting "BCM Unlock Single Door Setting";
CM_ SG_ 534 BCM_Buzzer_Req "BCM Buzzer Request";
CM_ SG_ 534 TailgateRemote "Remote Control PTG";
CM_ SG_ 534 RoomLampL "Room Lamp Low";
CM_ SG_ 534 RoomLampH "Room Lamp High";
CM_ SG_ 534 DimmerEN "Dimmer Enable";
CM_ SG_ 534 BCM_DoorLock_Sta "BCM Unlock Single Door Setting";
CM_ SG_ 534 HornCtrl "Horn Control";
CM_ SG_ 534 WisrBootReason "FDC wisr boot reason";
CM_ SG_ 534 PmicBootReason "FDC PMIC boot reason";
CM_ SG_ 560 CellVoltage01 "CellVoltage01";
CM_ SG_ 560 CellVoltage02 "CellVoltage02";
CM_ SG_ 560 CellVoltage03 "CellVoltage03";
CM_ SG_ 560 CellVoltage04 "CellVoltage04";
CM_ SG_ 560 CellVoltage05 "CellVoltage05";
CM_ SG_ 560 CellVoltage06 "CellVoltage06";
CM_ SG_ 560 CellVoltage07 "CellVoltage07";
CM_ SG_ 560 CellVoltage08 "CellVoltage08";
CM_ SG_ 560 CellVoltage09 "CellVoltage09";
CM_ SG_ 560 CellVoltage10 "CellVoltage10";
CM_ SG_ 560 CellVoltage11 "CellVoltage11";
CM_ SG_ 560 CellVoltage12 "CellVoltage12";
CM_ SG_ 560 CellVoltage13 "CellVoltage13";
CM_ SG_ 560 CellVoltage14 "CellVoltage14";
CM_ SG_ 560 CellVoltage15 "CellVoltage15";
CM_ SG_ 560 CellVoltage16 "CellVoltage16";
CM_ SG_ 560 CellVoltage17 "CellVoltage17";
CM_ SG_ 560 CellVoltage18 "CellVoltage18";
CM_ SG_ 560 CellVoltage19 "CellVoltage19";
CM_ SG_ 560 CellVoltage20 "CellVoltage20";
CM_ SG_ 560 CellVoltage21 "CellVoltage21";
CM_ SG_ 560 CellVoltage22 "CellVoltage22";
CM_ SG_ 560 CellVoltage23 "CellVoltage23";
CM_ SG_ 560 CellVoltage24 "CellVoltage24";
CM_ SG_ 560 CellVoltage25 "CellVoltage25";
CM_ SG_ 560 CellVoltage26 "CellVoltage26";
CM_ SG_ 560 CellVoltage27 "CellVoltage27";
CM_ SG_ 560 CellVoltage28 "CellVoltage28";
CM_ SG_ 560 CellVoltage29 "CellVoltage29";
CM_ SG_ 560 CellVoltage30 "CellVoltage30";
CM_ SG_ 560 CellVoltage31 "CellVoltage31";
CM_ SG_ 560 CellVoltage32 "CellVoltage32";
CM_ SG_ 561 CellVoltage33 "CellVoltage33";
CM_ SG_ 561 CellVoltage34 "CellVoltage34";
CM_ SG_ 561 CellVoltage35 "CellVoltage35";
CM_ SG_ 561 CellVoltage36 "CellVoltage36";
CM_ SG_ 561 CellVoltage37 "CellVoltage37";
CM_ SG_ 561 CellVoltage38 "CellVoltage38";
CM_ SG_ 561 CellVoltage39 "CellVoltage39";
CM_ SG_ 561 CellVoltage40 "CellVoltage40";
CM_ SG_ 561 CellVoltage41 "CellVoltage41";
CM_ SG_ 561 CellVoltage42 "CellVoltage42";
CM_ SG_ 561 CellVoltage43 "CellVoltage43";
CM_ SG_ 561 CellVoltage44 "CellVoltage44";
CM_ SG_ 561 CellVoltage45 "CellVoltage45";
CM_ SG_ 561 CellVoltage46 "CellVoltage46";
CM_ SG_ 561 CellVoltage47 "CellVoltage47";
CM_ SG_ 561 CellVoltage48 "CellVoltage48";
CM_ SG_ 561 CellVoltage49 "CellVoltage49";
CM_ SG_ 561 CellVoltage50 "CellVoltage50";
CM_ SG_ 561 CellVoltage51 "CellVoltage51";
CM_ SG_ 561 CellVoltage52 "CellVoltage52";
CM_ SG_ 561 CellVoltage53 "CellVoltage53";
CM_ SG_ 561 CellVoltage54 "CellVoltage54";
CM_ SG_ 561 CellVoltage55 "CellVoltage55";
CM_ SG_ 561 CellVoltage56 "CellVoltage56";
CM_ SG_ 561 CellVoltage57 "CellVoltage57";
CM_ SG_ 561 CellVoltage58 "CellVoltage58";
CM_ SG_ 561 CellVoltage59 "CellVoltage59";
CM_ SG_ 561 CellVoltage60 "CellVoltage60";
CM_ SG_ 561 CellVoltage61 "CellVoltage61";
CM_ SG_ 561 CellVoltage62 "CellVoltage62";
CM_ SG_ 561 CellVoltage63 "CellVoltage63";
CM_ SG_ 561 CellVoltage64 "CellVoltage64";
CM_ SG_ 562 CellVoltage65 "CellVoltage65";
CM_ SG_ 562 CellVoltage66 "CellVoltage66";
CM_ SG_ 562 CellVoltage67 "CellVoltage67";
CM_ SG_ 562 CellVoltage68 "CellVoltage68";
CM_ SG_ 562 CellVoltage69 "CellVoltage69";
CM_ SG_ 562 CellVoltage70 "CellVoltage70";
CM_ SG_ 562 CellVoltage71 "CellVoltage71";
CM_ SG_ 562 CellVoltage72 "CellVoltage72";
CM_ SG_ 562 CellVoltage73 "CellVoltage73";
CM_ SG_ 562 CellVoltage74 "CellVoltage74";
CM_ SG_ 562 CellVoltage75 "CellVoltage75";
CM_ SG_ 562 CellVoltage76 "CellVoltage76";
CM_ SG_ 562 CellVoltage77 "CellVoltage77";
CM_ SG_ 562 CellVoltage78 "CellVoltage78";
CM_ SG_ 562 CellVoltage79 "CellVoltage79";
CM_ SG_ 562 CellVoltage80 "CellVoltage80";
CM_ SG_ 562 CellVoltage81 "CellVoltage81";
CM_ SG_ 562 CellVoltage82 "CellVoltage82";
CM_ SG_ 562 CellVoltage83 "CellVoltage83";
CM_ SG_ 562 CellVoltage84 "CellVoltage84";
CM_ SG_ 562 CellVoltage85 "CellVoltage85";
CM_ SG_ 562 CellVoltage86 "CellVoltage86";
CM_ SG_ 562 CellVoltage87 "CellVoltage87";
CM_ SG_ 562 CellVoltage88 "CellVoltage88";
CM_ SG_ 562 CellVoltage89 "CellVoltage89";
CM_ SG_ 562 CellVoltage90 "CellVoltage90";
CM_ SG_ 562 CellVoltage91 "CellVoltage91";
CM_ SG_ 562 CellVoltage92 "CellVoltage92";
CM_ SG_ 562 CellVoltage93 "CellVoltage93";
CM_ SG_ 562 CellVoltage94 "CellVoltage94";
CM_ SG_ 562 CellVoltage95 "CellVoltage95";
CM_ SG_ 562 CellVoltage96 "CellVoltage96";
CM_ SG_ 563 CellVoltage97 "CellVoltage97";
CM_ SG_ 563 CellVoltage98 "CellVoltage98";
CM_ SG_ 563 CellVoltage99 "CellVoltage99";
CM_ SG_ 563 CellVoltage100 "CellVoltage100";
CM_ SG_ 563 CellVoltage101 "CellVoltage101";
CM_ SG_ 563 CellVoltage102 "CellVoltage102";
CM_ SG_ 563 CellVoltage103 "CellVoltage103";
CM_ SG_ 563 CellVoltage104 "CellVoltage104";
CM_ SG_ 563 CellVoltage105 "CellVoltage105";
CM_ SG_ 563 CellVoltage106 "CellVoltage106";
CM_ SG_ 563 CellVoltage107 "CellVoltage107";
CM_ SG_ 563 CellVoltage108 "CellVoltage108";
CM_ SG_ 563 CellVoltage109 "CellVoltage109";
CM_ SG_ 563 CellVoltage110 "CellVoltage110";
CM_ SG_ 563 CellVoltage111 "CellVoltage111";
CM_ SG_ 563 CellVoltage112 "CellVoltage112";
CM_ SG_ 563 CellVoltage113 "CellVoltage113";
CM_ SG_ 563 CellVoltage114 "CellVoltage114";
CM_ SG_ 563 CellVoltage115 "CellVoltage115";
CM_ SG_ 563 CellVoltage116 "CellVoltage116";
CM_ SG_ 563 CellVoltage117 "CellVoltage117";
CM_ SG_ 563 CellVoltage118 "CellVoltage118";
CM_ SG_ 563 CellVoltage119 "CellVoltage119";
CM_ SG_ 563 CellVoltage120 "CellVoltage120";
CM_ SG_ 563 CellVoltage121 "CellVoltage121";
CM_ SG_ 563 CellVoltage122 "CellVoltage122";
CM_ SG_ 563 CellVoltage123 "CellVoltage123";
CM_ SG_ 563 CellVoltage124 "CellVoltage124";
CM_ SG_ 563 CellVoltage125 "CellVoltage125";
CM_ SG_ 563 CellVoltage126 "CellVoltage126";
CM_ SG_ 563 CellVoltage127 "CellVoltage127";
CM_ SG_ 563 CellVoltage128 "CellVoltage128";
CM_ SG_ 809 HVBattSOCDis "HV battery pack Display SOC";
CM_ SG_ 809 HVBattSOC "HV battery pack SOC";
CM_ SG_ 809 HVBattPackVolt "BMS pack voltage";
CM_ SG_ 809 HVBChrgPwr "Total Charge kWh";
CM_ SG_ 809 HVBDrvPwr "Total drive kWh";
CM_ SG_ 809 HVBFullChrgPwr "Full charge energy";
CM_ SG_ 809 RemainChrgTime "Remaining charge time";
CM_ SG_ 809 HVBSOH "Battery SOH";
CM_ SG_ 809 HVBIsoImpedenceP "Isolated Impedance BP";
CM_ SG_ 809 HVBIsoImpedenceN "Isolated Impedance BN";
CM_ SG_ 809 Battsystfail_Num "Number of failures of rechargeable energy storage device";
CM_ SG_ 809 RechrgCyc "Charge Cycles";
CM_ SG_ 809 CellType "HVB Cell Type";
CM_ SG_ 809 ACChrgCurrDis "HVB AC charge current max display";
CM_ SG_ 809 HVBChrgPwrTotal "Total Charge kWh accumulation";
CM_ SG_ 809 HVBDrvPwrTotal "Total Discharge kWh accumulation";
CM_ SG_ 809 HVBattSOCDiff "Difference from Cell SOCMax to Cell SOCMin";
CM_ SG_ 809 SOC_UseLimit "SOC Use Limit";
CM_ SG_ 809 BMS_HVBattCellBalance_Sta "Battery Cell Balance Flag";
CM_ SG_ 820 MainPosstandard "MainPosstandard";
CM_ SG_ 820 MainChrgRlyNegOutterVoltage "MainChrgRlyNegOutterVoltage";
CM_ SG_ 820 MainChrgRlyPosOutterVoltage "MainChrgRlyPosOutterVoltage";
CM_ SG_ 820 MainRlyNegOutterVoltage "MainRlyNegOutterVoltage";
CM_ SG_ 820 G0standard "G0standard";
CM_ SG_ 820 MainRlyPosOutterVoltage "MainRlyPosOutterVoltage";
CM_ SG_ 820 MainRlyPosInnerVoltage "MainRlyPosInnerVoltage";
CM_ SG_ 820 MainChrgRlyPosSta "MainChrgRlyPosSta";
CM_ SG_ 820 MainChrgRlyNegSta "MainChrgRlyNegSta";
CM_ SG_ 820 MainRlyNegSta "MainRlyNegSta";
CM_ SG_ 820 MainRlyPosSta "MainRlyPosSta";
CM_ SG_ 820 MainChrgRlyNegDriReq "MainChrgRlyNegDriReq";
CM_ SG_ 820 MainChrgRlyPosDriReq "MainChrgRlyPosDriReq";
CM_ SG_ 820 MainRlyNegDriReq "MainRlyNegDriReq";
CM_ SG_ 820 MainRlyPosDriReq "MainRlyPosDriReq";
CM_ SG_ 820 TherRunawayErrMask "ThermalRunawayErrorMask";
CM_ SG_ 820 DCChrgCurrent "DCChargeCurrent";
CM_ SG_ 820 DCChrgVoltage "DCChargeVoltage";
CM_ SG_ 820 ACChrgStop "ACChargeStop";
CM_ SG_ 820 DCChrgStop "DCChargeStop";
CM_ SG_ 820 CurrentErrorID "Current Error ID NO.";
CM_ SG_ 884 Req_V2LSwOn "FD asks IVI popup wording for SW on.";
CM_ SG_ 884 Req_OBCV2LEna "FD trigs OBC V2L enabled.";
CM_ SG_ 884 Req_V2L_IVI_Popup "FD asks IVI popup wording for V2L fault.";
CM_ SG_ 886 ChrgCurType "Charging Current Type";
CM_ SG_ 886 HVBattErr "Battery error (HVBattFault)";
CM_ SG_ 886 FireDetErr "Fire detector";
CM_ SG_ 886 ChrgLampSta "Charge lamp status";
CM_ SG_ 898 CCU_ACportNTC1 "AC charging port NTC1";
CM_ SG_ 898 CCU_ACportNTC2 "AC charging port NTC2";
CM_ SG_ 921 Fr_MCU_SW_Ver "Front MCU Software version";
CM_ SG_ 921 Fr_MCU_HW_Ver "Front MCU Hardware version";
CM_ SG_ 925 Rr_MCU3_SW_Ver "Rear MCU Software version";
CM_ SG_ 925 Rr_MCU3_HW_Ver "Rear MCU Hardware version";
CM_ SG_ 992 HVBCellVoltMax "HV battery maximum cell Volt";
CM_ SG_ 992 HVBCellVoltMin "HV battery minimum cell Volt";
CM_ SG_ 992 CellTempAvg "Cell average temperature";
CM_ SG_ 992 MaxCellVolt_Num "Maximum cell voltage Number";
CM_ SG_ 992 MinCellVolt_Num "Minimum cell voltage Number";
CM_ SG_ 992 MaxCellTemp_Num "Maximum cell temperature Number";
CM_ SG_ 992 MinCellTemp_Num "Minimum cell temperature Number";
CM_ SG_ 992 HVBMTempMax "HV battery maximum module temperature";
CM_ SG_ 992 HVBMTempMin "HV battery minimum module temperature";
CM_ SG_ 992 Mtemp16 "Module temperature 16";
CM_ SG_ 992 Mtemp17 "Module temperature 17";
CM_ SG_ 992 Mtemp18 "Module temperature 18";
CM_ SG_ 992 Mtemp19 "Module temperature 19";
CM_ SG_ 992 Mtemp20 "Module temperature 20";
CM_ SG_ 992 Mtemp01 "Module Temperature01";
CM_ SG_ 992 Mtemp02 "Module Temperature02";
CM_ SG_ 992 Mtemp03 "Module Temperature03";
CM_ SG_ 992 Mtemp04 "Module Temperature04";
CM_ SG_ 992 Mtemp05 "Module Temperature05";
CM_ SG_ 992 Mtemp06 "Module Temperature06";
CM_ SG_ 992 Mtemp07 "Module Temperature07";
CM_ SG_ 992 Mtemp08 "Module Temperature08";
CM_ SG_ 992 Mtemp09 "Module Temperature09";
CM_ SG_ 992 Mtemp10 "Module Temperature10";
CM_ SG_ 992 Mtemp11 "Module Temperature11";
CM_ SG_ 992 Mtemp12 "Module Temperature12";
CM_ SG_ 992 Mtemp13 "Module Temperature13";
CM_ SG_ 992 Mtemp14 "Module Temperature14";
CM_ SG_ 992 Mtemp15 "Module Temperature15";

BA_DEF_ "NmType" STRING ;
BA_DEF_ "VersionYear" INT 2010 2999;
BA_DEF_ "ProtocolType" STRING ;
BA_DEF_ "NmMessageCount" INT 0 255;
BA_DEF_ "NmBaseAddress" HEX 1280 1407;
BA_DEF_ "DBName" STRING ;
BA_DEF_ "BusType" STRING ;
BA_DEF_ "Baudrate" INT 0 1000000;
BA_DEF_ "Datarate" INT 0 2000000;
BA_DEF_ BU_ "NodeLayerModules" STRING ;
BA_DEF_ BU_ "NmCAN" INT 1 2;
BA_DEF_ BU_ "ILUsed" ENUM "No","Yes";
BA_DEF_ BU_ "CANFD_CANFD_Gateway" ENUM "Yes","No";
BA_DEF_ BO_ "GenMsgSendType" ENUM "Cycle","NoMsgSendType","IfActive","Event","CA","CE";
BA_DEF_ BO_ "GenMsgNrOfRepetition" INT 0 0;
BA_DEF_ BO_ "GenMsgILSupport" ENUM "No","Yes";
BA_DEF_ BO_ "GenMsgDelayTime" INT 0 0;
BA_DEF_ BO_ "GenMsgCycleTimeFast" INT 0 0;
BA_DEF_ BO_ "GenMsgCycleTime" INT 0 0;
BA_DEF_ BO_ "DiagResponse" ENUM "No","Yes";
BA_DEF_ BO_ "DiagRequest" ENUM "No","Yes";
BA_DEF_ BO_ "NmMessage" ENUM "No","Yes";
BA_DEF_ BO_ "VFrameFormat" ENUM "StandardCAN","ExtendedCAN","reserved","reserved","reserved","reserved","reserved","reserved","reserved","reserved","reserved","reserved","reserved","reserved","StandardCAN_FD","ExtendedCAN_FD";
BA_DEF_ BO_ "GenMsgRequestable" INT 0 1;
BA_DEF_ BO_ "DataID_Hex" HEX 0 65535;
BA_DEF_ BO_ "DoIPLogicalAddress" STRING ;
BA_DEF_ BO_ "DataID" STRING ;
BA_DEF_ BO_ "CANFD_BRS" ENUM "0","1";
BA_DEF_ SG_ "GenSigInvalidValue" HEX 0 0;
BA_DEF_ SG_ "GenSigStartValue" HEX 0 0;
BA_DEF_ SG_ "GenSigInactiveValue" HEX 0 0;
BA_DEF_ SG_ "GenSigRoutingTimeoutValue_String" STRING ;
BA_DEF_ SG_ "GenSigRoutingTimeoutValue" HEX 0 0;
BA_DEF_ SG_ "GenSigSendType" ENUM "Cycle","OnWrite","OnWriteWithRepetition","OnChange","OnChangeWithRepetition","IfActive","IfActiveWithRepetition","NoSigSendType","vector_leerstring";
BA_DEF_ SG_ "SigType" ENUM "Default","Range","RangeSigned","ASCII","Discrete","Control","ReferencePGN","DTC","StringDelimiter","StringLength","StringLengthControl","MessageCounter","MessageChecksum";
BA_DEF_ SG_ "GenSigILSupport" ENUM "No","Yes";
BA_DEF_DEF_ "NmType" "AUTOSAR";
BA_DEF_DEF_ "VersionYear" 2023;
BA_DEF_DEF_ "ProtocolType" "CAN";
BA_DEF_DEF_ "NmMessageCount" 128;
BA_DEF_DEF_ "NmBaseAddress" 1280;
BA_DEF_DEF_ "DBName" "";
BA_DEF_DEF_ "BusType" "";
BA_DEF_DEF_ "Baudrate" 500000;
BA_DEF_DEF_ "Datarate" 2000000;
BA_DEF_DEF_ "NodeLayerModules" "CANoeILNLVector.dll";
BA_DEF_DEF_ "NmCAN" 2;
BA_DEF_DEF_ "ILUsed" "Yes";
BA_DEF_DEF_ "CANFD_CANFD_Gateway" "No";
BA_DEF_DEF_ "GenMsgSendType" "Cycle";
BA_DEF_DEF_ "GenMsgNrOfRepetition" 0;
BA_DEF_DEF_ "GenMsgILSupport" "Yes";
BA_DEF_DEF_ "GenMsgDelayTime" 0;
BA_DEF_DEF_ "GenMsgCycleTimeFast" 0;
BA_DEF_DEF_ "GenMsgCycleTime" 100;
BA_DEF_DEF_ "DiagResponse" "No";
BA_DEF_DEF_ "DiagRequest" "No";
BA_DEF_DEF_ "NmMessage" "No";
BA_DEF_DEF_ "VFrameFormat" "StandardCAN";
BA_DEF_DEF_ "GenMsgRequestable" 1;
BA_DEF_DEF_ "DataID_Hex" 0;
BA_DEF_DEF_ "DoIPLogicalAddress" "";
BA_DEF_DEF_ "DataID" "";
BA_DEF_DEF_ "CANFD_BRS" "1";
BA_DEF_DEF_ "GenSigInvalidValue" 0;
BA_DEF_DEF_ "GenSigStartValue" 0;
BA_DEF_DEF_ "GenSigInactiveValue" 0;
BA_DEF_DEF_ "GenSigRoutingTimeoutValue_String" "";
BA_DEF_DEF_ "GenSigRoutingTimeoutValue" 0;
BA_DEF_DEF_ "GenSigSendType" "Cycle";
BA_DEF_DEF_ "SigType" "Default";
BA_DEF_DEF_ "GenSigILSupport" "Yes";
BA_ "BusType" "CAN FD";
BA_ "ProtocolType" "CAN FD";
BA_ "DBName" "CAN3";
BA_ "CANFD_CANFD_Gateway" BU_ FUSION 0;
BA_ "GenMsgNrOfRepetition" BO_ 278 1;
BA_ "DataID_Hex" BO_ 278 13815;
BA_ "DataID" BO_ 278 "0x35F7";
BA_ "GenMsgCycleTimeFast" BO_ 278 10;
BA_ "GenMsgSendType" BO_ 278 3;
BA_ "VFrameFormat" BO_ 278 14;
BA_ "GenMsgCycleTime" BO_ 338 10;
BA_ "VFrameFormat" BO_ 338 14;
BA_ "DataID_Hex" BO_ 340 5185;
BA_ "GenMsgCycleTime" BO_ 340 10;
BA_ "DataID" BO_ 340 "0x1441";
BA_ "VFrameFormat" BO_ 340 14;
BA_ "DataID_Hex" BO_ 369 56380;
BA_ "GenMsgCycleTime" BO_ 369 10;
BA_ "DataID" BO_ 369 "0xDC3C";
BA_ "VFrameFormat" BO_ 369 14;
BA_ "GenMsgNrOfRepetition" BO_ 374 1;
BA_ "GenMsgCycleTimeFast" BO_ 374 10;
BA_ "GenMsgSendType" BO_ 374 5;
BA_ "VFrameFormat" BO_ 374 14;
BA_ "GenMsgNrOfRepetition" BO_ 378 1;
BA_ "DataID_Hex" BO_ 378 56123;
BA_ "DataID" BO_ 378 "0xDB3B";
BA_ "GenMsgCycleTimeFast" BO_ 378 10;
BA_ "GenMsgSendType" BO_ 378 5;
BA_ "VFrameFormat" BO_ 378 14;
BA_ "GenMsgNrOfRepetition" BO_ 385 1;
BA_ "DataID_Hex" BO_ 385 63901;
BA_ "DataID" BO_ 385 "0xF99D";
BA_ "GenMsgCycleTimeFast" BO_ 385 10;
BA_ "GenMsgSendType" BO_ 385 5;
BA_ "VFrameFormat" BO_ 385 14;
BA_ "VFrameFormat" BO_ 386 14;
BA_ "GenMsgNrOfRepetition" BO_ 389 1;
BA_ "DataID_Hex" BO_ 389 60213;
BA_ "GenMsgCycleTime" BO_ 389 10;
BA_ "DataID" BO_ 389 "0xEB35";
BA_ "GenMsgCycleTimeFast" BO_ 389 10;
BA_ "VFrameFormat" BO_ 389 14;
BA_ "GenMsgNrOfRepetition" BO_ 390 1;
BA_ "GenMsgCycleTimeFast" BO_ 390 10;
BA_ "GenMsgSendType" BO_ 390 5;
BA_ "VFrameFormat" BO_ 390 14;
BA_ "GenMsgNrOfRepetition" BO_ 395 1;
BA_ "GenMsgCycleTime" BO_ 395 10;
BA_ "GenMsgCycleTimeFast" BO_ 395 10;
BA_ "GenMsgSendType" BO_ 395 5;
BA_ "VFrameFormat" BO_ 395 14;
BA_ "DataID_Hex" BO_ 402 632;
BA_ "GenMsgCycleTime" BO_ 402 10;
BA_ "DataID" BO_ 402 "0x0278";
BA_ "VFrameFormat" BO_ 402 14;
BA_ "DataID_Hex" BO_ 406 38393;
BA_ "GenMsgCycleTime" BO_ 406 10;
BA_ "DataID" BO_ 406 "0x95F9";
BA_ "VFrameFormat" BO_ 406 14;
BA_ "GenMsgCycleTime" BO_ 408 200;
BA_ "VFrameFormat" BO_ 408 14;
BA_ "GenMsgCycleTime" BO_ 412 200;
BA_ "VFrameFormat" BO_ 412 14;
BA_ "GenMsgNrOfRepetition" BO_ 470 1;
BA_ "DataID_Hex" BO_ 470 58913;
BA_ "DataID" BO_ 470 "0xE621";
BA_ "GenMsgCycleTimeFast" BO_ 470 10;
BA_ "GenMsgSendType" BO_ 470 5;
BA_ "VFrameFormat" BO_ 470 14;
BA_ "GenMsgNrOfRepetition" BO_ 515 1;
BA_ "GenMsgCycleTime" BO_ 515 500;
BA_ "GenMsgCycleTimeFast" BO_ 515 50;
BA_ "GenMsgSendType" BO_ 515 5;
BA_ "VFrameFormat" BO_ 515 14;
BA_ "GenMsgNrOfRepetition" BO_ 534 1;
BA_ "GenMsgCycleTime" BO_ 534 200;
BA_ "GenMsgCycleTimeFast" BO_ 534 60;
BA_ "GenMsgSendType" BO_ 534 5;
BA_ "VFrameFormat" BO_ 534 14;
BA_ "VFrameFormat" BO_ 560 14;
BA_ "VFrameFormat" BO_ 561 14;
BA_ "VFrameFormat" BO_ 562 14;
BA_ "VFrameFormat" BO_ 563 14;
BA_ "GenMsgCycleTime" BO_ 809 1000;
BA_ "VFrameFormat" BO_ 809 14;
BA_ "VFrameFormat" BO_ 820 14;
BA_ "GenMsgNrOfRepetition" BO_ 884 1;
BA_ "GenMsgCycleTimeFast" BO_ 884 10;
BA_ "GenMsgSendType" BO_ 884 5;
BA_ "VFrameFormat" BO_ 884 14;
BA_ "GenMsgNrOfRepetition" BO_ 886 1;
BA_ "GenMsgCycleTime" BO_ 886 1000;
BA_ "GenMsgCycleTimeFast" BO_ 886 10;
BA_ "GenMsgSendType" BO_ 886 5;
BA_ "VFrameFormat" BO_ 886 14;
BA_ "GenMsgCycleTime" BO_ 898 200;
BA_ "VFrameFormat" BO_ 898 14;
BA_ "GenMsgCycleTime" BO_ 921 1000;
BA_ "VFrameFormat" BO_ 921 14;
BA_ "GenMsgCycleTime" BO_ 925 1000;
BA_ "VFrameFormat" BO_ 925 14;
BA_ "VFrameFormat" BO_ 992 14;
BA_ "GenSigSendType" SG_ 278 PwrSta 1;
BA_ "GenSigSendType" SG_ 278 CS_VCU1 1;
BA_ "GenSigSendType" SG_ 278 RC_VCU1 1;
BA_ "GenSigSendType" SG_ 278 Dr_SeatSta 1;
BA_ "GenSigSendType" SG_ 278 DynoModeStaChk 1;
BA_ "GenSigSendType" SG_ 278 CoastDwModeStaChk 1;
BA_ "GenSigSendType" SG_ 278 DemoModeStaChk 1;
BA_ "GenSigSendType" SG_ 278 LVChrgFuncStaChk 1;
BA_ "GenSigSendType" SG_ 278 DCDCVoltSetpoint 1;
BA_ "GenSigSendType" SG_ 278 DCDCEnaReq 1;
BA_ "GenSigSendType" SG_ 278 Fr_MCUEnaReq 1;
BA_ "GenSigSendType" SG_ 278 Rr_MCUEnaReq 1;
BA_ "GenSigSendType" SG_ 278 HVBatCnctReq 1;
BA_ "GenSigSendType" SG_ 278 ActiveDischReq 1;
BA_ "GenSigSendType" SG_ 278 PrkReq 1;
BA_ "GenSigSendType" SG_ 278 Fr_ActvDmpDisabReq 1;
BA_ "GenSigSendType" SG_ 278 Rr_ActvDmpDisabReq 1;
BA_ "GenSigSendType" SG_ 278 HVSysReadyToCharge 1;
BA_ "GenSigSendType" SG_ 278 ShiftGearPosn 1;
BA_ "GenSigInvalidValue" SG_ 278 LVChrgFuncStaChk 3;
BA_ "GenSigInvalidValue" SG_ 278 MSA_Crl_Sta 6;
BA_ "GenSigSendType" SG_ 278 MSA_Crl_Sta 1;
BA_ "GenSigInvalidValue" SG_ 278 DemoModeStaChk 3;
BA_ "GenSigInvalidValue" SG_ 278 CoastDwModeStaChk 3;
BA_ "GenSigInvalidValue" SG_ 278 DynoModeStaChk 3;
BA_ "GenSigInvalidValue" SG_ 338 RearAxlTrqReq_Drv 65535;
BA_ "GenSigStartValue" SG_ 338 RearAxlTrqReq_Drv 10600;
BA_ "GenSigInvalidValue" SG_ 338 FrntAxlTrqReq_Drv 65535;
BA_ "GenSigStartValue" SG_ 338 FrntAxlTrqReq_Drv 10600;
BA_ "GenSigInvalidValue" SG_ 338 VehSpeed 4095;
BA_ "GenSigRoutingTimeoutValue" SG_ 338 VehSpeed 4095;
BA_ "GenSigStartValue" SG_ 340 Fr_TMTqReq 530;
BA_ "GenSigStartValue" SG_ 340 Rr_TMTqReq 530;
BA_ "GenSigStartValue" SG_ 369 HVBPwrAvailDchrg30 1500;
BA_ "GenSigStartValue" SG_ 369 HVBPwrAvailChrg 1500;
BA_ "GenSigStartValue" SG_ 369 HVBPwrAvailDchrg 1500;
BA_ "GenSigStartValue" SG_ 369 HVBPwrAvailChrg60 1500;
BA_ "GenSigStartValue" SG_ 369 HVBPwrAvailDchrg60 1500;
BA_ "GenSigInvalidValue" SG_ 369 HVBattCurr 32767;
BA_ "GenSigStartValue" SG_ 369 HVBattCurr 10000;
BA_ "GenSigSendType" SG_ 374 ReChargerStaFromEvcc 3;
BA_ "GenSigStartValue" SG_ 374 OBCDCCurLm 255;
BA_ "GenSigSendType" SG_ 378 BMS_Warn_1 3;
BA_ "GenSigSendType" SG_ 378 BMS_Warn_2 3;
BA_ "GenSigSendType" SG_ 378 BMS_Warn_3 3;
BA_ "GenSigSendType" SG_ 378 BMS_Warn_4 3;
BA_ "GenSigSendType" SG_ 378 BMS_Warn_5 3;
BA_ "GenSigSendType" SG_ 378 BMS_Warn_6 3;
BA_ "GenSigSendType" SG_ 378 BMS_Warn_7 3;
BA_ "GenSigSendType" SG_ 378 BMS_Warn_8 3;
BA_ "GenSigSendType" SG_ 378 HVBOvrTempWarn 3;
BA_ "GenSigSendType" SG_ 378 HVBUndrTempWarn 3;
BA_ "GenSigSendType" SG_ 378 HVBOvrVoltErr 3;
BA_ "GenSigSendType" SG_ 378 HVBUndrVoltErr 3;
BA_ "GenSigSendType" SG_ 378 HVBShrtChrgCurrErr 3;
BA_ "GenSigSendType" SG_ 378 HVBShrtDischrgCurrErr 3;
BA_ "GenSigSendType" SG_ 378 HVBOvrChrgCurrErr 3;
BA_ "GenSigSendType" SG_ 378 HVBOvrDchrgCurErr 3;
BA_ "GenSigSendType" SG_ 378 HVBOvrTempErr 3;
BA_ "GenSigSendType" SG_ 378 HVBUndrTempErr 3;
BA_ "GenSigSendType" SG_ 378 HVBOvrSOCErr 3;
BA_ "GenSigSendType" SG_ 378 HVBUndrSOCErr 3;
BA_ "GenSigSendType" SG_ 378 HVBSOCJumpError 3;
BA_ "GenSigSendType" SG_ 378 HVBHVILErr 3;
BA_ "GenSigSendType" SG_ 378 DCChrgSysShockErr 3;
BA_ "GenSigSendType" SG_ 378 BMS_READY 3;
BA_ "GenSigSendType" SG_ 378 HVBContactorSta 3;
BA_ "GenSigSendType" SG_ 378 HVBPrechrgSta 3;
BA_ "GenSigSendType" SG_ 378 HVBTempDiffErr 3;
BA_ "GenSigSendType" SG_ 378 HVILSta 3;
BA_ "GenSigSendType" SG_ 378 HVBattReady4Pre 3;
BA_ "GenSigSendType" SG_ 378 ChrgPlugSta 3;
BA_ "GenSigSendType" SG_ 378 ExtChrgSta 3;
BA_ "GenSigSendType" SG_ 378 HVBPreheatPrecoolSta 3;
BA_ "GenSigSendType" SG_ 378 IsoDetSta 3;
BA_ "GenSigSendType" SG_ 378 SystemUncomErr 3;
BA_ "GenSigSendType" SG_ 378 CellUnconsistErr 3;
BA_ "GenSigSendType" SG_ 378 HVBCellOvrVoltWarn 3;
BA_ "GenSigSendType" SG_ 378 HVBCellUdrVoltWarn 3;
BA_ "GenSigSendType" SG_ 378 HVBCellOvrVoltErr 3;
BA_ "GenSigSendType" SG_ 378 HVBCellUndrVoltErr 3;
BA_ "GenSigSendType" SG_ 378 HVBCellUnbalanErr 3;
BA_ "GenSigSendType" SG_ 378 ChrgInLockReq 3;
BA_ "GenSigSendType" SG_ 378 DisChrgPlugErr 3;
BA_ "GenSigSendType" SG_ 378 HVBChrgErr 3;
BA_ "GenSigSendType" SG_ 378 V2LSta 3;
BA_ "GenSigInvalidValue" SG_ 385 Shifter_Handle_Cmd 255;
BA_ "GenSigSendType" SG_ 385 Shifter_Handle_Cmd 3;
BA_ "GenSigSendType" SG_ 385 Shifter_RC 3;
BA_ "GenSigSendType" SG_ 385 Shifter_CRC8 3;
BA_ "GenSigSendType" SG_ 385 Shifter_Fail_sta 3;
BA_ "GenSigStartValue" SG_ 386 Rr_Coolanttemp 40;
BA_ "GenSigStartValue" SG_ 386 sigClntTHvBattOut 120;
BA_ "GenSigStartValue" SG_ 386 sigCbnSolarLeft 253;
BA_ "GenSigStartValue" SG_ 386 sigCbnSolarRight 253;
BA_ "GenSigInvalidValue" SG_ 386 sigAmbAirT 255;
BA_ "GenSigInvalidValue" SG_ 386 sigAirIntenZon1St 15;
BA_ "GenSigStartValue" SG_ 386 Fr_Coolanttemp 40;
BA_ "GenSigStartValue" SG_ 389 OBCDCCurrInf 255;
BA_ "GenSigSendType" SG_ 390 CoolgFanActDuty 3;
BA_ "GenSigSendType" SG_ 390 APTC_ActFrRiPwr 3;
BA_ "GenSigInvalidValue" SG_ 390 FD_EWP1_Cmd 255;
BA_ "GenSigInvalidValue" SG_ 390 FD_EWP2_Cmd 255;
BA_ "GenSigInvalidValue" SG_ 390 FD_EWP3_Cmd 255;
BA_ "GenSigInvalidValue" SG_ 390 FD_FrWPTCHeatPwr_Cmd 255;
BA_ "GenSigSendType" SG_ 390 FD_FrWPTCHeatPwr_Cmd 3;
BA_ "GenSigSendType" SG_ 390 FD_RrAPTCHeatPwr_Cmd 3;
BA_ "GenSigInvalidValue" SG_ 390 FD_FrLeAPTCHeatPwr_Cmd 255;
BA_ "GenSigSendType" SG_ 390 FD_FrLeAPTCHeatPwr_Cmd 3;
BA_ "GenSigInvalidValue" SG_ 390 FD_FrRiAPTCHeatPwr_Cmd 255;
BA_ "GenSigSendType" SG_ 390 FD_FrRiAPTCHeatPwr_Cmd 3;
BA_ "GenSigSendType" SG_ 390 FD_Comp_Cmd 3;
BA_ "GenSigSendType" SG_ 390 FD_Blower_Cmd 3;
BA_ "GenSigSendType" SG_ 395 OBCV2LINVOTP 3;
BA_ "GenSigSendType" SG_ 395 OBCV2LInsuFault 3;
BA_ "GenSigSendType" SG_ 395 OBCV2LVoutOCP 3;
BA_ "GenSigSendType" SG_ 395 OBCV2LVoutOVP 3;
BA_ "GenSigSendType" SG_ 395 OBCV2LVoutUVP 3;
BA_ "GenSigInvalidValue" SG_ 402 Rr_EDUTqReqFbk 4095;
BA_ "GenSigStartValue" SG_ 402 Rr_EDUTqReqFbk 1022;
BA_ "GenSigStartValue" SG_ 402 Rr_EDURealTMTq 1022;
BA_ "GenSigStartValue" SG_ 402 Rr_TMSpd 17000;
BA_ "GenSigInvalidValue" SG_ 402 Rr_MCUDCBusVolt 65535;
BA_ "GenSigInvalidValue" SG_ 402 Rr_MCUDCBusCurr 32767;
BA_ "GenSigStartValue" SG_ 402 Rr_MCUDCBusCurr 15000;
BA_ "GenSigInvalidValue" SG_ 402 Rr_MCUTemp 511;
BA_ "GenSigInvalidValue" SG_ 402 Rr_TMTemp 511;
BA_ "GenSigInvalidValue" SG_ 402 Rr_TMid 32767;
BA_ "GenSigStartValue" SG_ 402 Rr_TMid 15000;
BA_ "GenSigInvalidValue" SG_ 402 Rr_TMiq 32767;
BA_ "GenSigStartValue" SG_ 402 Rr_TMiq 15000;
BA_ "GenSigInvalidValue" SG_ 402 Rr_MotorAvailTq 4095;
BA_ "GenSigInvalidValue" SG_ 402 Rr_RegenAvailTq 4095;
BA_ "GenSigInvalidValue" SG_ 402 Rr_MCUBAT 255;
BA_ "GenSigStartValue" SG_ 402 MCUWarn_R 7;
BA_ "GenSigInvalidValue" SG_ 406 Fr_EDUTqReqFbk 4095;
BA_ "GenSigStartValue" SG_ 406 Fr_EDUTqReqFbk 1022;
BA_ "GenSigStartValue" SG_ 406 Fr_TMSpd 17000;
BA_ "GenSigInvalidValue" SG_ 406 Fr_MCUDCBusVolt 65535;
BA_ "GenSigInvalidValue" SG_ 406 Fr_MCUDCBusCurr 32767;
BA_ "GenSigInvalidValue" SG_ 406 Fr_MCUTemp 511;
BA_ "GenSigInvalidValue" SG_ 406 Fr_TMTemp 511;
BA_ "GenSigInvalidValue" SG_ 406 Fr_TMid 32767;
BA_ "GenSigInvalidValue" SG_ 406 Fr_TMiq 32767;
BA_ "GenSigInvalidValue" SG_ 406 Fr_MotorAvailTq 4095;
BA_ "GenSigInvalidValue" SG_ 406 Fr_RegenAvailTq 4095;
BA_ "GenSigInvalidValue" SG_ 406 Fr_MCUBAT 255;
BA_ "GenSigStartValue" SG_ 406 MCUWarn_F 7;
BA_ "GenSigInvalidValue" SG_ 408 Fr_LLCTemp 511;
BA_ "GenSigInvalidValue" SG_ 408 Fr_LLCflowReq 63;
BA_ "GenSigInvalidValue" SG_ 408 Fr_EOP_SpdSet 4095;
BA_ "GenSigInvalidValue" SG_ 408 Fr_CoolanttempReq 511;
BA_ "GenSigStartValue" SG_ 408 Fr_CoolanttempReq 40;
BA_ "GenSigInvalidValue" SG_ 412 Rr_LLCTemp 511;
BA_ "GenSigStartValue" SG_ 412 Rr_LLCTemp 40;
BA_ "GenSigInvalidValue" SG_ 412 Rr_LLCflowReq 63;
BA_ "GenSigInvalidValue" SG_ 412 Rr_EOP_SpdSet 4095;
BA_ "GenSigInvalidValue" SG_ 412 Rr_CoolanttempReq 511;
BA_ "GenSigStartValue" SG_ 412 Rr_CoolanttempReq 40;
BA_ "GenSigSendType" SG_ 470 OBCFaultSta 3;
BA_ "GenSigSendType" SG_ 470 DCDCFaultSta 3;
BA_ "GenSigSendType" SG_ 470 OBCReady4Pre 3;
BA_ "GenSigSendType" SG_ 470 DCDCReady4Pre 3;
BA_ "GenSigStartValue" SG_ 470 OBCTemp 160;
BA_ "GenSigStartValue" SG_ 470 DCDCTemp 64;
BA_ "GenSigSendType" SG_ 470 DCDCTemp 3;
BA_ "GenSigStartValue" SG_ 470 OBCDCP 350;
BA_ "GenSigSendType" SG_ 470 DCDCEnaSta 3;
BA_ "GenSigSendType" SG_ 470 OBCEnaSta 3;
BA_ "GenSigStartValue" SG_ 470 OBCACCurrInf 40;
BA_ "GenSigSendType" SG_ 470 OBC_AC_Cur_Lim 3;
BA_ "GenSigSendType" SG_ 470 OBCV2LSta 3;
BA_ "GenSigSendType" SG_ 470 ReqOBCV2LEna 3;
BA_ "GenSigSendType" SG_ 515 AirBagFailCmd 3;
BA_ "GenSigSendType" SG_ 515 DriverSeatBeltCmd 3;
BA_ "GenSigSendType" SG_ 515 PsngrSeatBeltCmd 3;
BA_ "GenSigSendType" SG_ 515 PABSwitchCmd 3;
BA_ "GenSigSendType" SG_ 515 RDriverSeatBeltCmd 3;
BA_ "GenSigSendType" SG_ 515 RPsngrSeatBeltCmd 3;
BA_ "GenSigSendType" SG_ 515 RCenterSeatBeltCmd 3;
BA_ "GenSigSendType" SG_ 515 TLHPsngrSeatBeltCmd 3;
BA_ "GenSigSendType" SG_ 515 TRHPsngrSeatBeltCmd 3;
BA_ "GenSigSendType" SG_ 515 CrashOutputSts 3;
BA_ "GenSigSendType" SG_ 515 LifeCount_ABM1 3;
BA_ "GenSigSendType" SG_ 515 Checksum_ABM1 3;
BA_ "GenSigSendType" SG_ 534 DrDoorSW 3;
BA_ "GenSigSendType" SG_ 534 PsDoorSW 3;
BA_ "GenSigSendType" SG_ 534 RLDoorSW 3;
BA_ "GenSigSendType" SG_ 534 RRDoorSW 3;
BA_ "GenSigSendType" SG_ 534 AllDoorSW 3;
BA_ "GenSigSendType" SG_ 534 DoorLockIND 3;
BA_ "GenSigSendType" SG_ 534 HoodSW 3;
BA_ "GenSigSendType" SG_ 534 Tailgate_SW 3;
BA_ "GenSigSendType" SG_ 534 CTDCtrl 3;
BA_ "GenSigSendType" SG_ 534 Fr_ChargingDoorCtrl 3;
BA_ "GenSigSendType" SG_ 534 Rr_ChargingDoorCtrl 3;
BA_ "GenSigSendType" SG_ 534 CTDLockSW 3;
BA_ "GenSigSendType" SG_ 534 CTDUnlockSW 3;
BA_ "GenSigSendType" SG_ 534 MirrorDefog 3;
BA_ "GenSigSendType" SG_ 534 Rr_Defog 3;
BA_ "GenSigSendType" SG_ 534 TrunkRel 3;
BA_ "GenSigSendType" SG_ 534 TailgateHDSW 3;
BA_ "GenSigSendType" SG_ 534 MirrorCtrl 3;
BA_ "GenSigSendType" SG_ 534 Fr_Wiper_H 3;
BA_ "GenSigSendType" SG_ 534 Fr_Wiper_L 3;
BA_ "GenSigSendType" SG_ 534 Rr_Wiper 3;
BA_ "GenSigSendType" SG_ 534 WiperFixMode 3;
BA_ "GenSigSendType" SG_ 534 WasherCtrl 3;
BA_ "GenSigSendType" SG_ 534 L_Beam 3;
BA_ "GenSigSendType" SG_ 534 H_Beam 3;
BA_ "GenSigSendType" SG_ 534 PosLamp 3;
BA_ "GenSigSendType" SG_ 534 LDRL 3;
BA_ "GenSigSendType" SG_ 534 RDRL 3;
BA_ "GenSigSendType" SG_ 534 ReverseLamp 3;
BA_ "GenSigSendType" SG_ 534 BrakeLamp 3;
BA_ "GenSigSendType" SG_ 534 LBSD 3;
BA_ "GenSigSendType" SG_ 534 RBSD 3;
BA_ "GenSigSendType" SG_ 534 Fr_FogLamp 3;
BA_ "GenSigSendType" SG_ 534 Rr_FogLamp 3;
BA_ "GenSigSendType" SG_ 534 HazardSW 3;
BA_ "GenSigSendType" SG_ 534 LTurnLP 3;
BA_ "GenSigSendType" SG_ 534 RTurnLP 3;
BA_ "GenSigSendType" SG_ 534 AntitheftSta 3;
BA_ "GenSigSendType" SG_ 534 AntiTheftSeatFold 3;
BA_ "GenSigSendType" SG_ 534 CrashDetd 3;
BA_ "GenSigSendType" SG_ 534 L_APM_WdwEnable 3;
BA_ "GenSigInvalidValue" SG_ 534 Dimmer 127;
BA_ "GenSigSendType" SG_ 534 Dimmer 3;
BA_ "GenSigSendType" SG_ 534 LockSetting 3;
BA_ "GenSigSendType" SG_ 534 BCM_Buzzer_Req 3;
BA_ "GenSigSendType" SG_ 534 TailgateRemote 3;
BA_ "GenSigSendType" SG_ 534 RoomLampL 3;
BA_ "GenSigSendType" SG_ 534 RoomLampH 3;
BA_ "GenSigSendType" SG_ 534 DimmerEN 3;
BA_ "GenSigSendType" SG_ 534 BCM_DoorLock_Sta 3;
BA_ "GenSigSendType" SG_ 534 HornCtrl 3;
BA_ "GenSigInvalidValue" SG_ 560 CellVoltage01 65535;
BA_ "GenSigInvalidValue" SG_ 560 CellVoltage02 65535;
BA_ "GenSigInvalidValue" SG_ 560 CellVoltage03 65535;
BA_ "GenSigInvalidValue" SG_ 560 CellVoltage04 65535;
BA_ "GenSigInvalidValue" SG_ 560 CellVoltage05 65535;
BA_ "GenSigInvalidValue" SG_ 560 CellVoltage06 65535;
BA_ "GenSigInvalidValue" SG_ 560 CellVoltage07 65535;
BA_ "GenSigInvalidValue" SG_ 560 CellVoltage08 65535;
BA_ "GenSigInvalidValue" SG_ 560 CellVoltage09 65535;
BA_ "GenSigInvalidValue" SG_ 560 CellVoltage10 65535;
BA_ "GenSigInvalidValue" SG_ 560 CellVoltage11 65535;
BA_ "GenSigInvalidValue" SG_ 560 CellVoltage12 65535;
BA_ "GenSigInvalidValue" SG_ 560 CellVoltage13 65535;
BA_ "GenSigInvalidValue" SG_ 560 CellVoltage14 65535;
BA_ "GenSigInvalidValue" SG_ 560 CellVoltage15 65535;
BA_ "GenSigInvalidValue" SG_ 560 CellVoltage16 65535;
BA_ "GenSigInvalidValue" SG_ 560 CellVoltage17 65535;
BA_ "GenSigInvalidValue" SG_ 560 CellVoltage18 65535;
BA_ "GenSigInvalidValue" SG_ 560 CellVoltage19 65535;
BA_ "GenSigInvalidValue" SG_ 560 CellVoltage20 65535;
BA_ "GenSigInvalidValue" SG_ 560 CellVoltage21 65535;
BA_ "GenSigInvalidValue" SG_ 560 CellVoltage22 65535;
BA_ "GenSigInvalidValue" SG_ 560 CellVoltage23 65535;
BA_ "GenSigInvalidValue" SG_ 560 CellVoltage24 65535;
BA_ "GenSigInvalidValue" SG_ 560 CellVoltage25 65535;
BA_ "GenSigInvalidValue" SG_ 560 CellVoltage26 65535;
BA_ "GenSigInvalidValue" SG_ 560 CellVoltage27 65535;
BA_ "GenSigInvalidValue" SG_ 560 CellVoltage28 65535;
BA_ "GenSigInvalidValue" SG_ 560 CellVoltage29 65535;
BA_ "GenSigInvalidValue" SG_ 560 CellVoltage30 65535;
BA_ "GenSigInvalidValue" SG_ 560 CellVoltage31 65535;
BA_ "GenSigInvalidValue" SG_ 560 CellVoltage32 65535;
BA_ "GenSigInvalidValue" SG_ 561 CellVoltage33 65535;
BA_ "GenSigInvalidValue" SG_ 561 CellVoltage34 65535;
BA_ "GenSigInvalidValue" SG_ 561 CellVoltage35 65535;
BA_ "GenSigInvalidValue" SG_ 561 CellVoltage36 65535;
BA_ "GenSigInvalidValue" SG_ 561 CellVoltage37 65535;
BA_ "GenSigInvalidValue" SG_ 561 CellVoltage38 65535;
BA_ "GenSigInvalidValue" SG_ 561 CellVoltage39 65535;
BA_ "GenSigInvalidValue" SG_ 561 CellVoltage40 65535;
BA_ "GenSigInvalidValue" SG_ 561 CellVoltage41 65535;
BA_ "GenSigInvalidValue" SG_ 561 CellVoltage42 65535;
BA_ "GenSigInvalidValue" SG_ 561 CellVoltage43 65535;
BA_ "GenSigInvalidValue" SG_ 561 CellVoltage44 65535;
BA_ "GenSigInvalidValue" SG_ 561 CellVoltage45 65535;
BA_ "GenSigInvalidValue" SG_ 561 CellVoltage46 65535;
BA_ "GenSigInvalidValue" SG_ 561 CellVoltage47 65535;
BA_ "GenSigInvalidValue" SG_ 561 CellVoltage48 65535;
BA_ "GenSigInvalidValue" SG_ 561 CellVoltage49 65535;
BA_ "GenSigInvalidValue" SG_ 561 CellVoltage50 65535;
BA_ "GenSigInvalidValue" SG_ 561 CellVoltage51 65535;
BA_ "GenSigInvalidValue" SG_ 561 CellVoltage52 65535;
BA_ "GenSigInvalidValue" SG_ 561 CellVoltage53 65535;
BA_ "GenSigInvalidValue" SG_ 561 CellVoltage54 65535;
BA_ "GenSigInvalidValue" SG_ 561 CellVoltage55 65535;
BA_ "GenSigInvalidValue" SG_ 561 CellVoltage56 65535;
BA_ "GenSigInvalidValue" SG_ 561 CellVoltage57 65535;
BA_ "GenSigInvalidValue" SG_ 561 CellVoltage58 65535;
BA_ "GenSigInvalidValue" SG_ 561 CellVoltage59 65535;
BA_ "GenSigInvalidValue" SG_ 561 CellVoltage60 65535;
BA_ "GenSigInvalidValue" SG_ 561 CellVoltage61 65535;
BA_ "GenSigInvalidValue" SG_ 561 CellVoltage62 65535;
BA_ "GenSigInvalidValue" SG_ 561 CellVoltage63 65535;
BA_ "GenSigInvalidValue" SG_ 561 CellVoltage64 65535;
BA_ "GenSigInvalidValue" SG_ 562 CellVoltage65 65535;
BA_ "GenSigInvalidValue" SG_ 562 CellVoltage66 65535;
BA_ "GenSigInvalidValue" SG_ 562 CellVoltage67 65535;
BA_ "GenSigInvalidValue" SG_ 562 CellVoltage68 65535;
BA_ "GenSigInvalidValue" SG_ 562 CellVoltage69 65535;
BA_ "GenSigInvalidValue" SG_ 562 CellVoltage70 65535;
BA_ "GenSigInvalidValue" SG_ 562 CellVoltage71 65535;
BA_ "GenSigInvalidValue" SG_ 562 CellVoltage72 65535;
BA_ "GenSigInvalidValue" SG_ 562 CellVoltage73 65535;
BA_ "GenSigInvalidValue" SG_ 562 CellVoltage74 65535;
BA_ "GenSigInvalidValue" SG_ 562 CellVoltage75 65535;
BA_ "GenSigInvalidValue" SG_ 562 CellVoltage76 65535;
BA_ "GenSigInvalidValue" SG_ 562 CellVoltage77 65535;
BA_ "GenSigInvalidValue" SG_ 562 CellVoltage78 65535;
BA_ "GenSigInvalidValue" SG_ 562 CellVoltage79 65535;
BA_ "GenSigInvalidValue" SG_ 562 CellVoltage80 65535;
BA_ "GenSigInvalidValue" SG_ 562 CellVoltage81 65535;
BA_ "GenSigInvalidValue" SG_ 562 CellVoltage82 65535;
BA_ "GenSigInvalidValue" SG_ 562 CellVoltage83 65535;
BA_ "GenSigInvalidValue" SG_ 562 CellVoltage84 65535;
BA_ "GenSigInvalidValue" SG_ 562 CellVoltage85 65535;
BA_ "GenSigInvalidValue" SG_ 562 CellVoltage86 65535;
BA_ "GenSigInvalidValue" SG_ 562 CellVoltage87 65535;
BA_ "GenSigInvalidValue" SG_ 562 CellVoltage88 65535;
BA_ "GenSigInvalidValue" SG_ 562 CellVoltage89 65535;
BA_ "GenSigInvalidValue" SG_ 562 CellVoltage90 65535;
BA_ "GenSigInvalidValue" SG_ 562 CellVoltage91 65535;
BA_ "GenSigInvalidValue" SG_ 562 CellVoltage92 65535;
BA_ "GenSigInvalidValue" SG_ 562 CellVoltage93 65535;
BA_ "GenSigInvalidValue" SG_ 562 CellVoltage94 65535;
BA_ "GenSigInvalidValue" SG_ 562 CellVoltage95 65535;
BA_ "GenSigInvalidValue" SG_ 562 CellVoltage96 65535;
BA_ "GenSigInvalidValue" SG_ 563 CellVoltage97 65535;
BA_ "GenSigInvalidValue" SG_ 563 CellVoltage98 65535;
BA_ "GenSigInvalidValue" SG_ 563 CellVoltage99 65535;
BA_ "GenSigInvalidValue" SG_ 563 CellVoltage100 65535;
BA_ "GenSigInvalidValue" SG_ 563 CellVoltage101 65535;
BA_ "GenSigInvalidValue" SG_ 563 CellVoltage102 65535;
BA_ "GenSigInvalidValue" SG_ 563 CellVoltage103 65535;
BA_ "GenSigInvalidValue" SG_ 563 CellVoltage104 65535;
BA_ "GenSigInvalidValue" SG_ 563 CellVoltage105 65535;
BA_ "GenSigInvalidValue" SG_ 563 CellVoltage106 65535;
BA_ "GenSigInvalidValue" SG_ 563 CellVoltage107 65535;
BA_ "GenSigInvalidValue" SG_ 563 CellVoltage108 65535;
BA_ "GenSigInvalidValue" SG_ 563 CellVoltage109 65535;
BA_ "GenSigInvalidValue" SG_ 563 CellVoltage110 65535;
BA_ "GenSigInvalidValue" SG_ 563 CellVoltage111 65535;
BA_ "GenSigInvalidValue" SG_ 563 CellVoltage112 65535;
BA_ "GenSigInvalidValue" SG_ 563 CellVoltage113 65535;
BA_ "GenSigInvalidValue" SG_ 563 CellVoltage114 65535;
BA_ "GenSigInvalidValue" SG_ 563 CellVoltage115 65535;
BA_ "GenSigInvalidValue" SG_ 563 CellVoltage116 65535;
BA_ "GenSigInvalidValue" SG_ 563 CellVoltage117 65535;
BA_ "GenSigInvalidValue" SG_ 563 CellVoltage118 65535;
BA_ "GenSigInvalidValue" SG_ 563 CellVoltage119 65535;
BA_ "GenSigInvalidValue" SG_ 563 CellVoltage120 65535;
BA_ "GenSigInvalidValue" SG_ 563 CellVoltage121 65535;
BA_ "GenSigInvalidValue" SG_ 563 CellVoltage122 65535;
BA_ "GenSigInvalidValue" SG_ 563 CellVoltage123 65535;
BA_ "GenSigInvalidValue" SG_ 563 CellVoltage124 65535;
BA_ "GenSigInvalidValue" SG_ 563 CellVoltage125 65535;
BA_ "GenSigInvalidValue" SG_ 563 CellVoltage126 65535;
BA_ "GenSigInvalidValue" SG_ 563 CellVoltage127 65535;
BA_ "GenSigInvalidValue" SG_ 563 CellVoltage128 65535;
BA_ "GenSigInvalidValue" SG_ 809 HVBattSOCDis 255;
BA_ "GenSigInvalidValue" SG_ 809 HVBattSOC 255;
BA_ "GenSigInvalidValue" SG_ 809 HVBChrgPwr 1023;
BA_ "GenSigInvalidValue" SG_ 809 HVBDrvPwr 1023;
BA_ "GenSigInvalidValue" SG_ 809 HVBFullChrgPwr 1023;
BA_ "GenSigInvalidValue" SG_ 809 HVBSOH 255;
BA_ "GenSigInvalidValue" SG_ 809 Battsystfail_Num 255;
BA_ "GenSigInvalidValue" SG_ 809 RechrgCyc 262143;
BA_ "GenSigInvalidValue" SG_ 809 ACChrgCurrDis 32767;
BA_ "GenSigStartValue" SG_ 809 ACChrgCurrDis 10000;
BA_ "GenSigSendType" SG_ 884 Req_V2LSwOn 3;
BA_ "GenSigSendType" SG_ 884 Req_V2L_IVI_Popup 3;
BA_ "GenSigInvalidValue" SG_ 886 ChrgCurType 3;
BA_ "GenSigSendType" SG_ 886 ChrgCurType 3;
BA_ "GenSigSendType" SG_ 886 HVBattErr 3;
BA_ "GenSigSendType" SG_ 886 FireDetErr 3;
BA_ "GenSigSendType" SG_ 886 ChrgLampSta 3;
BA_ "GenSigStartValue" SG_ 898 CCU_ACportNTC1 48;
BA_ "GenSigStartValue" SG_ 898 CCU_ACportNTC2 48;
BA_ "GenSigInvalidValue" SG_ 992 HVBCellVoltMax 65535;
BA_ "GenSigInvalidValue" SG_ 992 HVBCellVoltMin 65535;
BA_ "GenSigInvalidValue" SG_ 992 CellTempAvg 255;
BA_ "GenSigStartValue" SG_ 992 CellTempAvg 40;
BA_ "GenSigInvalidValue" SG_ 992 MaxCellVolt_Num 255;
BA_ "GenSigInvalidValue" SG_ 992 MinCellVolt_Num 255;
BA_ "GenSigInvalidValue" SG_ 992 MaxCellTemp_Num 255;
BA_ "GenSigInvalidValue" SG_ 992 MinCellTemp_Num 255;
BA_ "GenSigInvalidValue" SG_ 992 HVBMTempMax 255;
BA_ "GenSigStartValue" SG_ 992 HVBMTempMax 40;
BA_ "GenSigInvalidValue" SG_ 992 HVBMTempMin 255;
BA_ "GenSigStartValue" SG_ 992 HVBMTempMin 40;
BA_ "GenSigInvalidValue" SG_ 992 Mtemp16 255;
BA_ "GenSigInvalidValue" SG_ 992 Mtemp17 255;
BA_ "GenSigInvalidValue" SG_ 992 Mtemp18 255;
BA_ "GenSigInvalidValue" SG_ 992 Mtemp19 255;
BA_ "GenSigInvalidValue" SG_ 992 Mtemp20 255;
BA_ "GenSigInvalidValue" SG_ 992 Mtemp01 255;
BA_ "GenSigInvalidValue" SG_ 992 Mtemp02 255;
BA_ "GenSigInvalidValue" SG_ 992 Mtemp03 255;
BA_ "GenSigInvalidValue" SG_ 992 Mtemp04 255;
BA_ "GenSigInvalidValue" SG_ 992 Mtemp05 255;
BA_ "GenSigInvalidValue" SG_ 992 Mtemp06 255;
BA_ "GenSigInvalidValue" SG_ 992 Mtemp07 255;
BA_ "GenSigInvalidValue" SG_ 992 Mtemp08 255;
BA_ "GenSigInvalidValue" SG_ 992 Mtemp09 255;
BA_ "GenSigInvalidValue" SG_ 992 Mtemp10 255;
BA_ "GenSigInvalidValue" SG_ 992 Mtemp11 255;
BA_ "GenSigInvalidValue" SG_ 992 Mtemp12 255;
BA_ "GenSigInvalidValue" SG_ 992 Mtemp13 255;
BA_ "GenSigInvalidValue" SG_ 992 Mtemp14 255;
BA_ "GenSigInvalidValue" SG_ 992 Mtemp15 255;
VAL_ 278 PwrSta 5 "READY" 4 "ON" 3 "STANDBY" 2 "OFF-After-Run" 1 "OFF-Charging" 0 "OFF";
VAL_ 278 DCDCEnaReq 1 "Enable Request" 0 "Disable";
VAL_ 278 Fr_MCUEnaReq 1 "Enable Request" 0 "Disable";
VAL_ 278 Rr_MCUEnaReq 1 "Enable Request" 0 "Disable";
VAL_ 278 HVBatCnctReq 1 "Connect" 0 "Disconnect";
VAL_ 278 ActiveDischReq 1 "Request Active Discharge" 0 "No Request";
VAL_ 278 PrkReq 1 "Parking Requested" 0 "Parking Released";
VAL_ 278 Fr_ActvDmpDisabReq 1 "Disable Request" 0 "Enable Request";
VAL_ 278 Rr_ActvDmpDisabReq 1 "Disable Request" 0 "Enable Request";
VAL_ 278 HVSysReadyToCharge 3 "Disable" 2 "Fault" 1 "Allow charge" 0 "Allow discharge";
VAL_ 278 ShiftGearPosn 7 "Reverse" 6 "Failure" 5 "Drive" 4 "Neutral" 3 "Not used" 2 "Not used" 1 "Not used" 0 "Park";
VAL_ 278 LVChrgFuncStaChk 2 "Invalid" 1 "On" 0 "Off";
VAL_ 278 MSA_Crl_Sta 7 "Pedal Override" 6 "Invalid" 5 "Error" 4 "Over Speed" 3 "Under Speed" 2 "Active" 1 "Standby" 0 "Off";
VAL_ 278 DemoModeStaChk 2 "Invalid" 1 "Ready" 0 "Not ready";
VAL_ 278 CoastDwModeStaChk 2 "Invalid" 1 "Ready" 0 "Not ready";
VAL_ 278 DynoModeStaChk 2 "Invalid" 1 "Ready" 0 "Not ready";
VAL_ 278 Dr_SeatSta 2 "Invalid" 1 "Seat occupied" 0 "Seat empty";
VAL_ 338 Fr_PTCS_Active 1 "Active" 0 "Inactive";
VAL_ 338 Rr_PTCS_Active 1 "Active" 0 "Inactive";
VAL_ 374 ReChargerStaFromEvcc 3 "Invalid" 2 "Untrusted" 1 "On" 0 "Off";
VAL_ 378 BMS_Warn_1 1 "fault" 0 "No fault";
VAL_ 378 BMS_Warn_2 1 "fault" 0 "No fault";
VAL_ 378 BMS_Warn_3 1 "fault" 0 "No fault";
VAL_ 378 BMS_Warn_4 1 "fault" 0 "No fault";
VAL_ 378 BMS_Warn_5 1 "fault" 0 "No fault";
VAL_ 378 BMS_Warn_6 1 "fault" 0 "No fault";
VAL_ 378 BMS_Warn_7 1 "fault" 0 "No fault";
VAL_ 378 BMS_Warn_8 1 "fault" 0 "No fault";
VAL_ 378 HVBOvrTempWarn 2 "Warn2" 1 "Warn1" 0 "No fault";
VAL_ 378 HVBUndrTempWarn 2 "Warn2" 1 "Warn1" 0 "No fault";
VAL_ 378 HVBOvrVoltErr 1 "fault" 0 "No fault";
VAL_ 378 HVBUndrVoltErr 1 "fault" 0 "No fault";
VAL_ 378 HVBShrtChrgCurrErr 1 "fault" 0 "No fault";
VAL_ 378 HVBShrtDischrgCurrErr 1 "fault" 0 "No fault";
VAL_ 378 HVBOvrChrgCurrErr 1 "fault" 0 "No fault";
VAL_ 378 HVBOvrDchrgCurErr 1 "fault" 0 "No fault";
VAL_ 378 HVBOvrTempErr 1 "fault" 0 "No fault";
VAL_ 378 HVBUndrTempErr 1 "fault" 0 "No fault";
VAL_ 378 HVBOvrSOCErr 1 "fault" 0 "No fault";
VAL_ 378 HVBUndrSOCErr 1 "fault" 0 "No fault";
VAL_ 378 HVBSOCJumpError 1 "fault" 0 "No fault";
VAL_ 378 HVBHVILErr 1 "fault" 0 "No fault";
VAL_ 378 DCChrgSysShockErr 1 "fault" 0 "No fault";
VAL_ 378 BMS_READY 1 "Ready" 0 "Not ready";
VAL_ 378 HVBContactorSta 1 "Closed" 0 "Open";
VAL_ 378 HVBPrechrgSta 3 "precharge fail" 2 "precharge finished" 1 "precharge" 0 "not precharge";
VAL_ 378 HVBTempDiffErr 1 "fault" 0 "No fault";
VAL_ 378 HVILSta 1 "Opened" 0 "Closed";
VAL_ 378 HVBattReady4Pre 2 "Fault" 1 "Ready" 0 "Not Ready";
VAL_ 378 ChrgPlugSta 3 "Plug-in dectected" 2 "DC Plug in" 1 "AC Plug in" 0 "No plug";
VAL_ 378 ExtChrgSta 3 "Fault" 2 "Charging Completed" 1 "Charging" 0 "No action";
VAL_ 378 HVBPreheatPrecoolSta 2 "Precool" 1 "Preheat" 0 "Default";
VAL_ 378 IsoDetSta 1 "Fault detected" 0 "No fault detected";
VAL_ 378 SystemUncomErr 1 "fault" 0 "No fault";
VAL_ 378 CellUnconsistErr 1 "fault" 0 "No fault";
VAL_ 378 HVBCellOvrVoltWarn 2 "Warn2" 1 "Warn1" 0 "No fault";
VAL_ 378 HVBCellUdrVoltWarn 2 "Warn2" 1 "Warn1" 0 "No fault";
VAL_ 378 HVBCellOvrVoltErr 1 "fault" 0 "No fault";
VAL_ 378 HVBCellUndrVoltErr 1 "fault" 0 "No fault";
VAL_ 378 HVBCellUnbalanErr 1 "fault" 0 "No fault";
VAL_ 378 ChrgInLockReq 2 "Unlock" 1 "Lock" 0 "No action";
VAL_ 378 DisChrgPlugErr 2 "(un)lock request invalid" 1 "plug-in incomplete" 0 "Normal";
VAL_ 378 HVBChrgErr 4 "EVFault" 3 "EVStop" 2 "EvseFAULT" 1 "SocMeetTarget" 0 "OK";
VAL_ 378 V2LSta 3 "Invalid" 2 "SW on" 1 "V2L Adapter Plug-in" 0 "No plug";
VAL_ 385 Shifter_Handle_Cmd 255 "invalid" 7 "Reverse" 5 "Drive" 4 "Neutral" 2 "Park" 0 "Default";
VAL_ 385 Shifter_Fail_sta 3 "shifter failure" 2 "Hall failure" 1 "P button failure" 0 "normal";
VAL_ 386 FD_AGS_Cmd 208 "78^Deg" 240 "90^Deg" 176 "66^Deg" 144 "54^Deg" 112 "42^Deg" 80 "30^Deg" 48 "18^Deg" 16 "6^Deg" 224 "84^Deg" 192 "72^Deg" 160 "60^Deg" 128 "48^Deg" 96 "36^Deg" 64 "24^Deg" 32 "12^Deg" 0 "0^Deg";
VAL_ 386 CabinMode 9 "Cabin Heating Mode 2" 8 "Cabin Heating Mode 1" 7 "Cabin Dehumidity Mode 4" 6 "Cabin Dehumidity Mode 3" 5 "Cabin Dehumidity Mode 2" 4 "Cabin Dehumidity Mode 1" 3 "Mode 1" 2 "Comp On" 1 "Comp Off" 0 "OFF";
VAL_ 386 BatteryMode 5 "Active Heating" 4 "Passive Heating" 3 "Isothermal Cycle" 2 "Passive Cooling" 1 "Active Cooling" 0 "OFF";
VAL_ 386 FD_RecyAuto_Cmd 6 "reserved" 5 "reserved" 4 "100% out recycle" 3 "70% out recycle" 2 "50% out recycle" 1 "30% out recycle" 0 "0% out recycle";
VAL_ 386 EDriveMode 2 "Waste Heat Recovery" 1 "Cooling" 0 "OFF";
VAL_ 386 HPThermalRecoveryReq 1 "Request" 0 "Not Request";
VAL_ 386 sigHvacSt 1 "ON" 0 "OFF";
VAL_ 386 sigRecircSt 1 "ON" 0 "OFF";
VAL_ 386 sigDfrstSt 1 "ON" 0 "OFF";
VAL_ 386 CCU_SyncLampSts 1 "Lamp ON" 0 "Lamp OFF";
VAL_ 386 sigAirIntenZon3St 15 "Invalid" 14 "Reserved" 11 "Reserved" 10 "NOT set" 9 "Level 8" 8 "Level 7" 7 "Level 6" 6 "Level 5" 5 "Level 4" 4 "Level 3" 3 "Level 2" 2 "Level 1" 1 "OFF" 0 "NO display / No request";
VAL_ 386 sigAirIntenZon1St 15 "Invalid" 14 "Reserved" 11 "Reserved" 10 "NOT set" 9 "Level 8" 8 "Level 7" 7 "Level 6" 6 "Level 5" 5 "Level 4" 4 "Level 3" 3 "Level 2" 2 "Level 1" 1 "OFF" 0 "NO display / No request";
VAL_ 386 sigWindDirZon3St 7 "NOT Set / Reserved" 6 "All open" 5 "Face + Screen" 4 "DEFOG" 3 "Foot + Screen" 2 "Foot" 1 "Bilevel" 0 "FACE";
VAL_ 386 CCU_FrtOnOffLampSts 1 "Lamp ON" 0 "Lamp OFF";
VAL_ 386 sigWindDirZon1St 7 "NOT Set / Reserved" 6 "All open" 5 "Face + Screen" 4 "DEFOG" 3 "Foot + Screen" 2 "Foot" 1 "Bilevel" 0 "FACE";
VAL_ 386 CCU_RrOnOffLampSts 1 "Lamp ON" 0 "Lamp OFF";
VAL_ 386 CCU_ACMaxLampSts 1 "Lamp ON" 0 "Lamp OFF";
VAL_ 386 CCU_AutoLampSts 1 "Lamp ON" 0 "Lamp OFF";
VAL_ 386 CCU_AutoMidLampSts 1 "Lamp ON" 0 "Lamp OFF";
VAL_ 386 CCU_EcoSts 1 "Lamp ON" 0 "Lamp OFF";
VAL_ 386 CCU_ACLampSts 1 "Lamp ON" 0 "Lamp OFF";
VAL_ 386 CCU_HEATMaxLampSts 1 "Lamp ON" 0 "Lamp OFF";
VAL_ 389 DCDCPreCompleted 2 "False" 1 "True" 0 "Default";
VAL_ 389 OBCPreCompleted 2 "Default" 1 "True" 0 "False";
VAL_ 389 OBCWakeup4Plugin 1 "True" 0 "False";
VAL_ 390 FD_EWP1_Cmd 255 "Invalid" 250 "Maxmum Speed" 50 "Minmum Speed" 0 "Stop";
VAL_ 390 FD_EWP2_Cmd 255 "Invalid" 250 "Maxmum Speed" 50 "Minmum Speed" 0 "Stop";
VAL_ 390 FD_EWP3_Cmd 255 "Invalid" 250 "Maxmum Speed" 50 "Minmum Speed" 0 "Stop";
VAL_ 390 FD_RrAPTCHeatPwr_Cmd 255 "Invalid" 201 "~ 0xFE Reserved" 0 "~0xC8 actual value";
VAL_ 390 FD_FrLeAPTCHeatPwr_Cmd 255 "Invalid" 201 "~0xFE Reserved" 0 "~ 0xC8 actual value";
VAL_ 390 FD_FrRiAPTCHeatPwr_Cmd 255 "Invalid" 201 "~0xFE Reserved" 0 "~ 0xC8 actual value";
VAL_ 390 CCU_CbnPreEstimdTi 63 "Invalid" 62 "Reserved" 61 "Reserved" 60 "Normal" 0 "Normal";
VAL_ 390 CCU_CbnPreACWkSts 3 "Fail" 2 "Success" 1 "Init" 0 "No Request";
VAL_ 390 DeiceModReq 1 "Request" 0 "Not Request";
VAL_ 390 CCU_CbnPreSts 3 "Reserved" 2 "Calculate Estimated Time Status" 1 "ON" 0 "OFF";
VAL_ 390 CCU_HiVoltageReq 1 "High Voltage Request" 0 "High Voltage not Request";
VAL_ 390 FD_FWV_Cmd 1 "Open Port 1 to Port 4, Port 2 to port 3" 0 "Open Port 1 to Port 2, Port 3 to port 4";
VAL_ 390 ACSubMode 7 "mode 7" 6 "mode 6" 5 "Mode 5" 4 "Mode 4" 3 "Mode 3" 2 "Mode 2" 1 "Mode 1" 0 "OFF";
VAL_ 390 FD_SOTXV_Cmd 1 "Close" 0 "Open";
VAL_ 390 FD_SOV1_Cmd 1 "Close" 0 "Open";
VAL_ 390 FD_SOV2_Cmd 1 "Close" 0 "Open";
VAL_ 390 FD_SOV3_Cmd 1 "Close" 0 "Open";
VAL_ 395 OBCV2LVinUVP 1 "Fault" 0 "Not Fault";
VAL_ 395 OBCV2LVinOVP 1 "Fault" 0 "Not Fault";
VAL_ 395 OBCV2LINVOTP 1 "Fault" 0 "Not Fault";
VAL_ 395 OBCV2LInsuFault 1 "Fault" 0 "Not Fault";
VAL_ 395 OBCV2LVoutOCP 1 "Fault" 0 "Not Fault";
VAL_ 395 OBCV2LVoutOVP 1 "Fault" 0 "Not Fault";
VAL_ 395 OBCV2LVoutUVP 1 "Fault" 0 "Not Fault";
VAL_ 402 Rr_MCUEnaSta 1 "Enable is ready" 0 "Disabled";
VAL_ 402 Rr_EDUOpratingSta 1 "Speed" 0 "Torque";
VAL_ 402 Rr_EDURotateDirction 2 "Backward" 1 "Forward" 0 "Stop";
VAL_ 402 Rr_MCUReady4Pre 1 "Ready for Precharge" 0 "Not Ready for Precharge";
VAL_ 402 Rr_ActvDmpDisabSta 1 "Disable" 0 "Enable";
VAL_ 402 Rr_EDUDrtSta 1 "Torque Derating" 0 "Normal operation";
VAL_ 402 Rr_MCUDischrgSta 1 "Discharge completed" 0 "Discharge not ready";
VAL_ 402 Rr_MCUReady 1 "Ready" 0 "Not Ready";
VAL_ 402 Rr_MCUErr 33 "Rolling counter_Err" 32 "Checksum_Err" 31 "BAT_High_Err" 30 "DrvrBrdOff" 29 "HWth3PHmax" 28 "AD2SInit_Err" 27 "B_OFFSET_Err" 26 "IGN_High_Err" 25 "IGBT_TEMP_sensing_Err" 24 "Motor_TEMP_sensing_Err" 23 "UVW_sensing_Err" 22 "UVW_unbalance" 21 "VPN_sensing_Err" 20 "IGN_Low_Err" 19 "BAT_Low_Err" 18 "Motor_TEMP_OVER" 17 "thRDX_ERROR" 16 "RDX_LOS" 15 "C_OFFSET_Err" 14 "A_OFFSET_Err" 13 "th3PHmax" 12 "H_sensor_Fault" 11 "VPN_250V" 10 "VPN_450V" 9 "HCU_miss" 8 "BMS_miss" 7 "UVW_open" 6 "IGBT_TEMP_OVER" 5 "P30BAT_ERR" 4 "DIR_ERR" 3 "Motor_speed_OVER" 2 "IGBT_FAULT" 1 "Motor_stuck" 0 "Nofault";
VAL_ 402 Rr_MCUIGN_sta 1 "MCU IGN On" 0 "MCU IGN Off";
VAL_ 402 Rr_MCUSysSta 15 "Not used" 14 "Not used" 13 "Not used" 12 "Not used" 11 "Not used" 10 "Not used" 9 "Resolver Adjust." 8 "Diag Service" 7 "Discharge" 6 "AfterRun" 5 "Failure" 4 "Speed Control" 3 "Torque Control" 2 "Ready" 1 "Stand by" 0 "Initial Diag";
VAL_ 402 MCUWarn_R 7 "MCU Normal(NO Error)" 3 "ERR LVL3" 2 "ERR LVL2" 1 "ERR LVL1" 0 "ERR LVL0";
VAL_ 406 Fr_MCUEnaSta 1 "Enable is ready" 0 "Disabled";
VAL_ 406 Fr_EDUOpratingSta 1 "Speed" 0 "Torque";
VAL_ 406 Fr_EDURotateDirction 2 "Backward" 1 "Forward" 0 "Stop";
VAL_ 406 Fr_MCUReady4Pre 1 "Ready for Precharge" 0 "Not Ready for Precharge";
VAL_ 406 Fr_ActvDmpDisabSta 1 "Disable" 0 "Enable";
VAL_ 406 Fr_EDUDrtSta 1 "Torque Derating" 0 "Normal operation";
VAL_ 406 Fr_MCUDischrgSta 1 "Discharge completed" 0 "Discharge not ready";
VAL_ 406 Fr_MCUErr 33 "Rolling counter_Err" 32 "Checksum_Err" 31 "BAT_High_Err" 30 "DrvrBrdOff" 29 "HWth3PHmax" 28 "AD2SInit_Err" 27 "B_OFFSET_Err" 26 "IGN_High_Err" 25 "IGBT_TEMP_sensing_Err" 24 "Motor_TEMP_sensing_Err" 23 "UVW_sensing_Err" 22 "UVW_unbalance" 21 "VPN_sensing_Err" 20 "IGN_Low_Err" 19 "BAT_Low_Err" 18 "Motor_TEMP_OVER" 17 "thRDX_ERROR" 16 "RDX_LOS" 15 "C_OFFSET_Err" 14 "A_OFFSET_Err" 13 "th3PHmax" 12 "H_sensor_Fault" 11 "VPN_250V" 10 "VPN_450V" 9 "HCU_miss" 8 "BMS_miss" 7 "UVW_open" 6 "IGBT_TEMP_OVER" 5 "P30BAT_ERR" 4 "DIR_ERR" 3 "Motor_speed_OVER" 2 "IGBT_FAULT" 1 "Motor_stuck" 0 "Nofault";
VAL_ 406 Fr_MCUIGN_sta 1 "MCU IGN On" 0 "MCU IGN Off";
VAL_ 406 Fr_MCUSysSta 15 "Not used" 14 "Not used" 13 "Not used" 12 "Not used" 11 "Not used" 10 "Not used" 9 "Resolver Adjust." 8 "Diag Service" 7 "Discharge" 6 "AfterRun" 5 "Failure" 4 "Speed Control" 3 "Torque Control" 2 "Ready" 1 "Stand by" 0 "Initial Diag";
VAL_ 406 MCUWarn_F 7 "MCU Normal(NO Error)" 3 "ERR LVL3" 2 "ERR LVL2" 1 "ERR LVL1" 0 "ERR LVL0";
VAL_ 406 Fr_MCUReady 1 "Ready" 0 "Not Ready";
VAL_ 408 Fr_Failcodehistory1 2 "Past failure" 1 "Latest failure" 0 "Nothing";
VAL_ 408 Fr_Failcodehistory2 2 "Past failure" 1 "Latest failure" 0 "Nothing";
VAL_ 408 Fr_TMTempWarn 2 "Reserve" 1 "Warning" 0 "Normal";
VAL_ 408 Fr_MCUTempWarn 2 "Reserve" 1 "Warning" 0 "Normal";
VAL_ 412 Rr_Failcodehistory1 2 "Past failure" 1 "Latest failure" 0 "Nothing";
VAL_ 412 Rr_Failcodehistory2 2 "Past failure" 1 "Latest failure" 0 "Nothing";
VAL_ 412 Rr_TMTempWarn 2 "Reserve" 1 "Warning" 0 "Normal";
VAL_ 412 Rr_MCUTempWarn 2 "Reserve" 1 "Warning" 0 "Normal";
VAL_ 470 OBCFaultSta 3 "Invalid" 2 "Any Fault" 1 "Working" 0 "Not Working";
VAL_ 470 DCDCFaultSta 3 "Any Fault LV2" 2 "Any Fault LV1" 1 "Working" 0 "Not Working";
VAL_ 470 OBCReady4Pre 1 "Ready" 0 "Not ready";
VAL_ 470 DCDCReady4Pre 1 "Ready" 0 "Not ready";
VAL_ 470 DCDCEnaSta 1 "DCDC enabled" 0 "DCDC disabled";
VAL_ 470 OBCPluginSta 1 "Plugin" 0 "Not Plugin";
VAL_ 470 OBCEnaSta 1 "Enabled" 0 "Disabled";
VAL_ 470 OBC_AC_Cur_Lim 3 "80A" 2 "45A" 1 "32A" 0 "16A";
VAL_ 470 OBCV2LSta 2 "Fault" 1 "Working" 0 "Not working";
VAL_ 470 ReqOBCV2LEna 2 "Internal V2L discharge" 1 "External V2L discharge" 0 "Not request for V2L discharge";
VAL_ 515 AirBagFailCmd 1 "Lamp ON" 0 "Lamp OFF";
VAL_ 515 DriverSeatBeltCmd 1 "Lamp ON" 0 "Lamp OFF";
VAL_ 515 PsngrSeatBeltCmd 1 "Lamp ON" 0 "Lamp OFF";
VAL_ 515 PABSwitchCmd 1 "Lamp ON" 0 "Lamp OFF";
VAL_ 515 RDriverSeatBeltCmd 1 "Lamp ON" 0 "Lamp OFF";
VAL_ 515 RPsngrSeatBeltCmd 1 "Lamp ON" 0 "Lamp OFF";
VAL_ 515 RCenterSeatBeltCmd 1 "Lamp ON" 0 "Lamp OFF";
VAL_ 515 TLHPsngrSeatBeltCmd 1 "Lamp ON" 0 "Lamp OFF";
VAL_ 515 TRHPsngrSeatBeltCmd 1 "Lamp ON" 0 "Lamp OFF";
VAL_ 515 CrashOutputSts 8 "Right hand side" 2 "Front First level" 16 "Left hand side" 0 "No crash";
VAL_ 534 DrDoorSW 1 "Open" 0 "Close";
VAL_ 534 PsDoorSW 1 "Open" 0 "Close";
VAL_ 534 RLDoorSW 1 "Open" 0 "Close";
VAL_ 534 RRDoorSW 1 "Open" 0 "Close";
VAL_ 534 AllDoorSW 1 "Any Door Open" 0 "Close";
VAL_ 534 DoorLockIND 1 "On" 0 "Off";
VAL_ 534 HoodSW 1 "Open" 0 "Close";
VAL_ 534 Tailgate_SW 1 "Open" 0 "Close";
VAL_ 534 CTDCtrl 3 "Lock All Door" 2 "Unlock All Door" 1 "Unlock Driver Door" 0 "No Command";
VAL_ 534 Fr_ChargingDoorCtrl 3 "Undefined" 2 "Lock" 1 "Unlock" 0 "No Command";
VAL_ 534 Rr_ChargingDoorCtrl 3 "Undefined" 2 "Lock" 1 "Unlock" 0 "No Command";
VAL_ 534 CTDLockSW 1 "Press" 0 "Release";
VAL_ 534 CTDUnlockSW 1 "Press" 0 "Release";
VAL_ 534 MirrorDefog 1 "On" 0 "Off";
VAL_ 534 Rr_Defog 1 "On" 0 "Off";
VAL_ 534 TrunkRel 1 "Release" 0 "Off";
VAL_ 534 TailgateHDSW 1 "Press" 0 "Release";
VAL_ 534 MirrorCtrl 3 "Undefined" 2 "Unfold" 1 "Fold" 0 "No Command";
VAL_ 534 Fr_Wiper_H 1 "On" 0 "Off";
VAL_ 534 Fr_Wiper_L 1 "On" 0 "Off";
VAL_ 534 Rr_Wiper 1 "On" 0 "Off";
VAL_ 534 WiperFixMode 1 "On" 0 "Off";
VAL_ 534 WasherCtrl 3 "Undefined" 2 "Rear Washer" 1 "Front Washer" 0 "No Command";
VAL_ 534 L_Beam 1 "On" 0 "Off";
VAL_ 534 H_Beam 1 "On" 0 "Off";
VAL_ 534 PosLamp 1 "On" 0 "Off";
VAL_ 534 LDRL 1 "On" 0 "Off";
VAL_ 534 RDRL 1 "On" 0 "Off";
VAL_ 534 ReverseLamp 1 "On" 0 "Off";
VAL_ 534 BrakeLamp 1 "On" 0 "Off";
VAL_ 534 LBSD 1 "On" 0 "Off";
VAL_ 534 RBSD 1 "On" 0 "Off";
VAL_ 534 Fr_FogLamp 1 "On" 0 "Off";
VAL_ 534 Rr_FogLamp 1 "On" 0 "Off";
VAL_ 534 HazardSW 1 "On" 0 "Off";
VAL_ 534 LTurnLP 1 "On" 0 "Off";
VAL_ 534 RTurnLP 1 "On" 0 "Off";
VAL_ 534 AntitheftSta 3 "Alarm Status" 2 "Wait for Rearm Status" 1 "Arm Status" 0 "Disarm Status";
VAL_ 534 AntiTheftSeatFold 1 "Fold" 0 "No Request";
VAL_ 534 CrashDetd 1 "Crash detected" 0 "Crash not detected";
VAL_ 534 L_APM_WdwEnable 1 "Normal" 0 "Inhibit";
VAL_ 534 LockSetting 1 "Unlock Single Door" 0 "Unlock All Door";
VAL_ 534 BCM_Buzzer_Req 1 "Request" 0 "No Request";
VAL_ 534 TailgateRemote 3 "Invalid" 2 "Handle Request" 1 "Remote Request" 0 "No Request";
VAL_ 534 RoomLampL 1 "ON" 0 "OFF";
VAL_ 534 RoomLampH 1 "ON" 0 "OFF";
VAL_ 534 DimmerEN 1 "Enable" 0 "Disable";
VAL_ 534 BCM_DoorLock_Sta 1 "Lock" 0 "Unlock";
VAL_ 534 HornCtrl 1 "ON" 0 "OFF";
VAL_ 809 CellType 2 "AB battery" 1 "NCM" 0 "LFP";
VAL_ 809 SOC_UseLimit 2 "12%, limited" 1 "6%, limited" 0 "3%, normal";
VAL_ 809 BMS_HVBattCellBalance_Sta 1 "Balance Enable" 0 "Balance Disable";
VAL_ 820 MainChrgRlyPosSta 3 "Error" 2 "Closed" 1 "Open" 0 "None";
VAL_ 820 MainChrgRlyNegSta 3 "Error" 2 "Closed" 1 "Open" 0 "None";
VAL_ 820 MainRlyNegSta 3 "Error" 2 "Closed" 1 "Open" 0 "None";
VAL_ 820 MainRlyPosSta 3 "Error" 2 "Closed" 1 "Open" 0 "None";
VAL_ 820 MainChrgRlyNegDriReq 3 "Error" 2 "Closed" 1 "Open" 0 "None";
VAL_ 820 MainChrgRlyPosDriReq 3 "Error" 2 "Closed" 1 "Open" 0 "None";
VAL_ 820 MainRlyNegDriReq 3 "Error" 2 "Closed" 1 "Open" 0 "None";
VAL_ 820 MainRlyPosDriReq 3 "Error" 2 "Closed" 1 "Open" 0 "None";
VAL_ 884 Req_V2LSwOn 1 "Request for V2L plug switch on" 0 "Not request for V2L plug switch on";
VAL_ 884 Req_OBCV2LEna 2 "Internal V2L discharge" 1 "External V2L discharge" 0 "Not request for V2L discharge";
VAL_ 884 Req_V2L_IVI_Popup 6 "Request IVI popup 'V2L Fault'" 5 "Request IVI popup 'V2L Time up'" 4 "Request IVI popup 'SOC is too low'" 3 "Request IVI popup 'Stop by V2L SOC Set'" 2 "Request IVI popup 'V2L plug-in and V2L SW off'" 1 "Request IVI popup 'Check V2L Plug'" 0 "Not request";
VAL_ 886 ChrgCurType 3 "BC" 2 "DC" 1 "AC" 0 "None";
VAL_ 886 HVBattErr 1 "Battery Error" 0 "None";
VAL_ 886 FireDetErr 1 "Fault" 0 "Normal";
VAL_ 886 ChrgLampSta 3 "Fault" 2 "Green light on" 1 "Red light on" 0 "No action";
